VERSION ""

NS_ :

BS_:

BU_: BCM TPMS PEPS IC MP5 DDWS NV EATC TAC ESCL GW

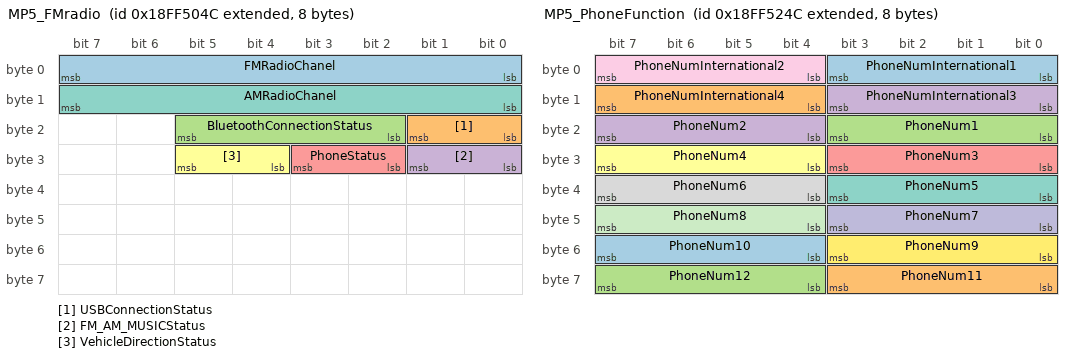
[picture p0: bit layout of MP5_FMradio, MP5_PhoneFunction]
BO_ 2566869068 MP5_FMradio: 8 MP5
 SG_ FMRadioChanel : 0|8@1+ (0.1,87.5) [87.5|108] "MHz"  IC
 SG_ USBConnectionStatus : 16|2@1+ (1,0) [0|3] ""  IC
 SG_ BluetoothConnectionStatus : 18|4@1+ (1,0) [0|15] ""  IC
 SG_ FM_AM_MUSICStatus : 24|2@1+ (1,0) [0|3] ""  IC
 SG_ PhoneStatus : 26|2@1+ (1,0) [0|3] ""  IC
 SG_ VehicleDirectionStatus : 28|2@1+ (1,0) [0|3] ""  IC
 SG_ AMRadioChanel : 8|8@1+ (9,522) [522|1629] "KHz"  IC

BO_ 2566869324 MP5_SongORName: 8 MP5
 SG_ EHC5_St_FrameType : 0|3@1+ (1,0) [0|3] ""  IC

BO_ 2566869580 MP5_PhoneFunction: 8 MP5
 SG_ PhoneNumInternational1 : 0|4@1+ (1,0) [0|9] ""  IC
 SG_ PhoneNumInternational4 : 12|4@1+ (1,0) [0|9] ""  IC
 SG_ PhoneNum1 : 16|4@1+ (1,0) [0|9] ""  IC
 SG_ PhoneNum2 : 20|4@1+ (1,0) [0|9] ""  IC
 SG_ PhoneNum3 : 24|4@1+ (1,0) [0|9] ""  IC
 SG_ PhoneNum4 : 28|4@1+ (1,0) [0|9] ""  IC
 SG_ PhoneNum5 : 32|4@1+ (1,0) [0|9] ""  IC
 SG_ PhoneNum6 : 36|4@1+ (1,0) [0|9] ""  IC
 SG_ PhoneNumInternational2 : 4|4@1+ (1,0) [0|9] ""  IC
 SG_ PhoneNum7 : 40|4@1+ (1,0) [0|9] ""  IC
 SG_ PhoneNum8 : 44|4@1+ (1,0) [0|9] ""  IC
 SG_ PhoneNum9 : 48|4@1+ (1,0) [0|9] ""  IC
 SG_ PhoneNum10 : 52|4@1+ (1,0) [0|9] ""  IC
 SG_ PhoneNum11 : 56|4@1+ (1,0) [0|9] ""  IC
 SG_ PhoneNum12 : 60|4@1+ (1,0) [0|9] ""  IC
 SG_ PhoneNumInternational3 : 8|4@1+ (1,0) [0|9] ""  IC

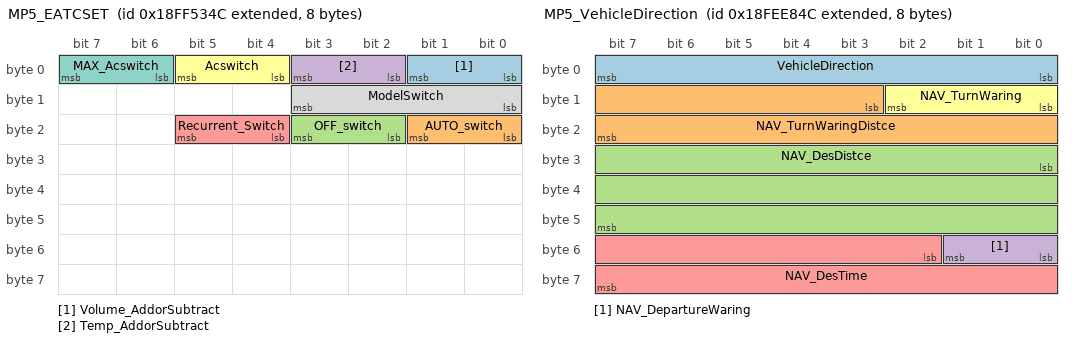
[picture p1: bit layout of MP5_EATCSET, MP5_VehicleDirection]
BO_ 2566869836 MP5_EATCSET: 8 MP5
 SG_ Volume_AddorSubtract : 0|2@1+ (1,0) [0|3] ""  EATC
 SG_ AUTO_switch : 16|2@1+ (1,0) [0|3] ""  EATC
 SG_ OFF_switch : 18|2@1+ (1,0) [0|3] ""  EATC
 SG_ Temp_AddorSubtract : 2|2@1+ (1,0) [0|3] ""  EATC
 SG_ Recurrent_Switch : 20|2@1+ (1,0) [0|3] ""  EATC
 SG_ Acswitch : 4|2@1+ (1,0) [0|3] ""  EATC
 SG_ MAX_Acswitch : 6|2@1+ (1,0) [0|3] ""  EATC
 SG_ ModelSwitch : 8|4@1+ (1,0) [0|15] ""  EATC

BO_ 2566842444 MP5_VehicleDirection: 8 MP5
 SG_ VehicleDirection : 0|8@1+ (1,0) [0|255] ""  IC
 SG_ NAV_TurnWaringDistce : 11|13@1+ (2,0) [0|10000] "m"  IC
 SG_ NAV_DesDistce : 24|24@1+ (1,0) [0|16777200] "m"  IC
 SG_ NAV_DepartureWaring : 48|2@1+ (1,0) [0|3] ""  IC
 SG_ NAV_DesTime : 50|14@1+ (1,0) [0|16383] "min分钟"  IC
 SG_ NAV_TurnWaring : 8|3@1+ (1,0) [0|7] ""  IC

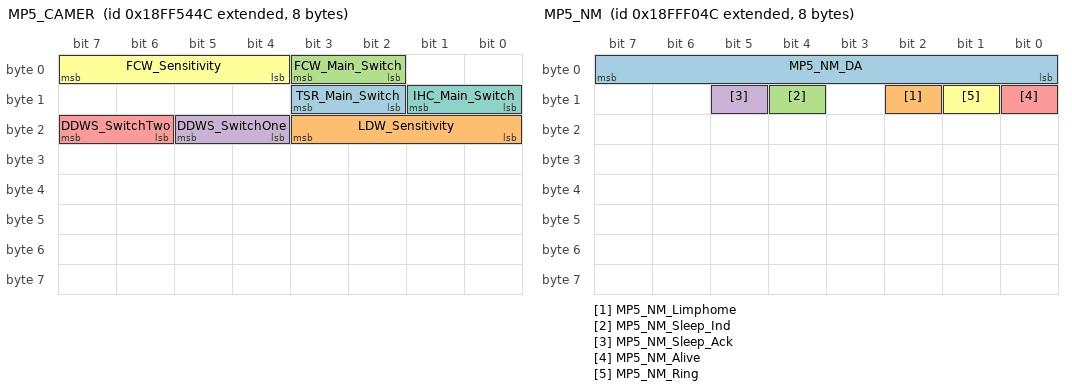
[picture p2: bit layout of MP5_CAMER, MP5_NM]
BO_ 2566870092 MP5_CAMER: 8 MP5
 SG_ TSR_Main_Switch : 10|2@1+ (1,0) [0|3] ""  GW
 SG_ LDW_Sensitivity : 16|4@1+ (1,0) [0|15] ""  GW
 SG_ FCW_Main_Switch : 2|2@1+ (1,0) [0|3] ""  GW
 SG_ DDWS_SwitchOne : 20|2@1+ (1,0) [0|3] ""  DDWS,GW
 SG_ DDWS_SwitchTwo : 22|2@1+ (1,0) [0|3] ""  DDWS,GW
 SG_ FCW_Sensitivity : 4|4@1+ (1,0) [0|15] ""  GW
 SG_ IHC_Main_Switch : 8|2@1+ (1,0) [0|3] ""  GW

BO_ 2566910028 MP5_NM: 8 MP5
 SG_ MP5_NM_DA : 0|8@1+ (1,0) [0|255] ""  BCM,PEPS,IC,EATC
 SG_ MP5_NM_Limphome : 10|1@1+ (1,0) [0|1] ""  BCM,PEPS,IC,EATC
 SG_ MP5_NM_Sleep_Ind : 12|1@1+ (1,0) [0|1] ""  BCM,PEPS,IC,EATC
 SG_ MP5_NM_Sleep_Ack : 13|1@1+ (1,0) [0|1] ""  BCM,PEPS,IC,EATC
 SG_ MP5_NM_Alive : 8|1@1+ (1,0) [0|1] ""  BCM,PEPS,IC,EATC
 SG_ MP5_NM_Ring : 9|1@1+ (1,0) [0|1] ""  BCM,PEPS,IC,EATC

BO_ 2566834764 MP5DM1CLuster: 8 MP5

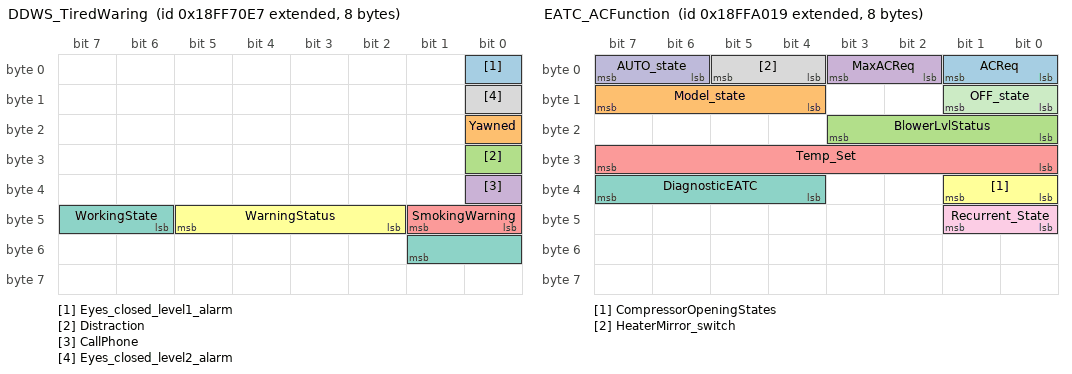
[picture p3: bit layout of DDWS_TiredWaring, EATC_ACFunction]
BO_ 2566877415 DDWS_TiredWaring: 8 DDWS
 SG_ Eyes_closed_level1_alarm : 0|1@1+ (1,0) [0|1] ""  IC,GW
 SG_ Yawned : 16|1@1+ (1,0) [0|1] ""  IC,GW
 SG_ Distraction : 24|1@1+ (1,0) [0|1] ""  IC,GW
 SG_ CallPhone : 32|1@1+ (1,0) [0|1] ""  IC,GW
 SG_ SmokingWarning : 40|2@1+ (1,0) [0|3] ""  GW
 SG_ WarningStatus : 42|4@1+ (1,0) [0|15] ""  IC,GW
 SG_ WorkingState : 46|4@1+ (1,0) [0|15] ""  IC,MP5,GW
 SG_ Eyes_closed_level2_alarm : 8|1@1+ (1,0) [0|1] ""  IC,GW

BO_ 2566877671 DDWS_CloseEyeTime: 8 DDWS
 SG_ Eyes_closed_Time : 0|8@1+ (1,0) [0|255] ""  GW

BO_ 2566834919 DDWS_DM1CLuster: 8 DDWS

BO_ 2566889497 EATC_ACFunction: 8 EATC
 SG_ ACReq : 0|2@1+ (1,0) [0|3] ""  BCM,MP5,GW
 SG_ Model_state : 12|4@1+ (1,0) [0|15] ""  MP5,GW
 SG_ BlowerLvlStatus : 16|4@1+ (1,0) [0|15] ""  MP5,GW
 SG_ MaxACReq : 2|2@1+ (1,0) [0|3] ""  MP5,GW
 SG_ Temp_Set : 24|8@1+ (1,0) [0|255] ""  MP5,GW
 SG_ CompressorOpeningStates : 32|2@1+ (1,0) [0|3] ""  BCM,GW
 SG_ DiagnosticEATC : 36|4@1+ (1,0) [0|15] ""  IC,GW
 SG_ HeaterMirror_switch : 4|2@1+ (1,0) [0|3] ""  BCM,MP5,GW
 SG_ Recurrent_State : 40|2@1+ (1,0) [0|3] ""  MP5,GW
 SG_ AUTO_state : 6|2@1+ (1,0) [0|3] ""  MP5,GW
 SG_ OFF_state : 8|2@1+ (1,0) [0|3] ""  MP5,GW

BO_ 2566841377 EATC_SHUTDN: 8 EATC
 SG_ A_C_CompressorSwitch : 22|2@1+ (1,0) [0|3] ""  GW

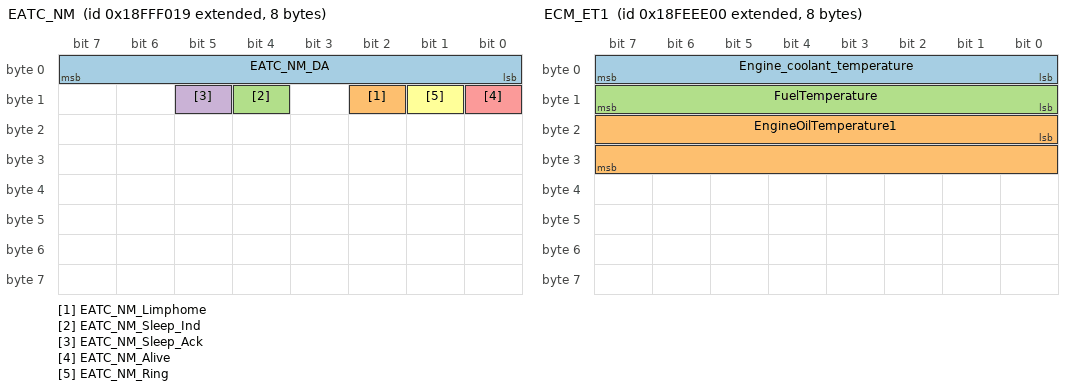
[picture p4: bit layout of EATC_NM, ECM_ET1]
BO_ 2566909977 EATC_NM: 8 EATC
 SG_ EATC_NM_DA : 0|8@1+ (1,0) [0|255] ""  BCM,PEPS,IC,MP5
 SG_ EATC_NM_Limphome : 10|1@1+ (1,0) [0|1] ""  BCM,PEPS,IC,MP5
 SG_ EATC_NM_Sleep_Ind : 12|1@1+ (1,0) [0|1] ""  BCM,PEPS,IC,MP5
 SG_ EATC_NM_Sleep_Ack : 13|1@1+ (1,0) [0|1] ""  BCM,PEPS,IC,MP5
 SG_ EATC_NM_Alive : 8|1@1+ (1,0) [0|1] ""  BCM,PEPS,IC,MP5
 SG_ EATC_NM_Ring : 9|1@1+ (1,0) [0|1] ""  BCM,PEPS,IC,MP5

BO_ 2566834713 EATCDM1CLuster: 8 EATC

BO_ 2566843904 ECM_ET1: 8 GW
 SG_ Engine_coolant_temperature : 0|8@1+ (1,-40) [-40|210] "°C"  IC,EATC
 SG_ EngineOilTemperature1 : 16|16@1+ (0.03125,-273) [-273|1735] "°C"  IC
 SG_ FuelTemperature : 8|8@1+ (1,-40) [-40|210] "°C"  IC

BO_ 2566844672 ECM_CCVS: 8 GW
 SG_ Two_speed_axle_switch : 0|2@1+ (1,0) [0|3] "" Vector__XXX
 SG_ Parking_brake_switch : 2|2@1+ (1,0) [0|3] ""  BCM,MP5,DDWS
 SG_ Cruise_Control_active : 24|2@1+ (1,0) [0|3] ""  IC,DDWS
 SG_ Cruise_Control_enable_switch : 26|2@1+ (1,0) [0|3] "" Vector__XXX
 SG_ Status_of_brake_switch : 28|2@1+ (1,0) [0|3] ""  PEPS,DDWS
 SG_ Status_of_clutch_switch : 30|2@1+ (1,0) [0|3] ""  BCM
 SG_ Cruise_Control_set_switch : 32|2@1+ (1,0) [0|3] "" Vector__XXX
 SG_ Cruise_Control_coast_switch : 34|2@1+ (1,0) [0|3] "" Vector__XXX
 SG_ Cruise_Control_resume_switch : 36|2@1+ (1,0) [0|3] "" Vector__XXX
 SG_ Cruise_Control_accelerate_switch : 38|2@1+ (1,0) [0|3] "" Vector__XXX
 SG_ Charge_Mode : 4|4@1+ (1,0) [0|15] "" Vector__XXX
 SG_ Cruise_Control_set_speed : 40|8@1+ (1,0) [0|250] "km/h" Vector__XXX
 SG_ PTO_state : 48|5@1+ (1,0) [0|31] "SED" Vector__XXX
 SG_ Cruise_Control_state : 53|3@1+ (1,0) [0|7] "SED" Vector__XXX
 SG_ IdleIncrementSwitch : 56|2@1+ (1,0) [0|3] "SED" Vector__XXX
 SG_ IdleDecrementSwitch : 58|2@1+ (1,0) [0|3] "SED" Vector__XXX
 SG_ EngineTestModeSwitch : 60|2@1+ (1,0) [0|3] "SED" Vector__XXX
 SG_ Engine_shutdown_override_switch : 62|2@1+ (1,0) [0|3] "SED" Vector__XXX
 SG_ Wheel_based_vehicle_speed : 8|16@1+ (0.00390625,0) [0|251] "km/h" Vector__XXX

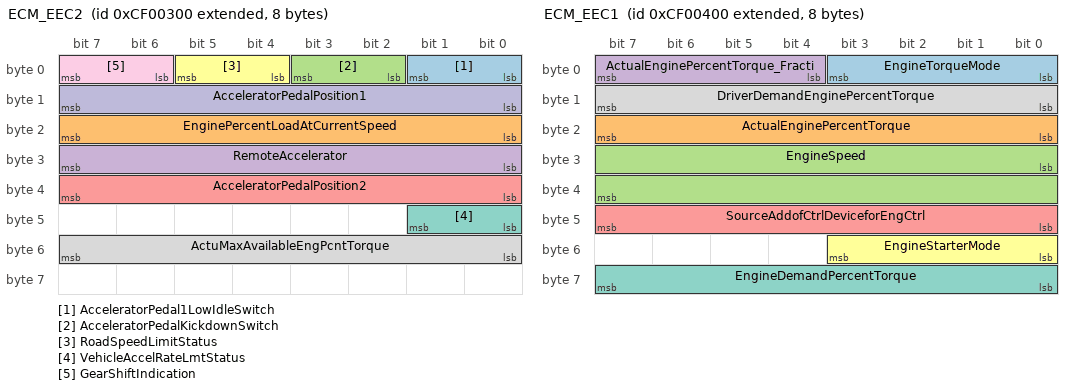
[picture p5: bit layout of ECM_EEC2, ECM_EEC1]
BO_ 2364539648 ECM_EEC2: 8 GW
 SG_ AcceleratorPedal1LowIdleSwitch : 0|2@1+ (1,0) [0|3] "" Vector__XXX
 SG_ EnginePercentLoadAtCurrentSpeed : 16|8@1+ (1,0) [0|125] "%" Vector__XXX
 SG_ AcceleratorPedalKickdownSwitch : 2|2@1+ (1,0) [0|3] "" Vector__XXX
 SG_ RemoteAccelerator : 24|8@1+ (0.4,0) [0|100] "%" Vector__XXX
 SG_ AcceleratorPedalPosition2 : 32|8@1+ (0.4,0) [0|100] "%" Vector__XXX
 SG_ RoadSpeedLimitStatus : 4|2@1+ (1,0) [0|3] "" Vector__XXX
 SG_ VehicleAccelRateLmtStatus : 40|2@1+ (1,0) [0|3] "" Vector__XXX
 SG_ ActuMaxAvailableEngPcntTorque : 48|8@1+ (0.4,0) [0|100] "%" Vector__XXX
 SG_ GearShiftIndication : 6|2@1+ (1,0) [0|3] "" Vector__XXX
 SG_ AcceleratorPedalPosition1 : 8|8@1+ (0.4,0) [0|100] "%"  DDWS

BO_ 2364539904 ECM_EEC1: 8 GW
 SG_ EngineTorqueMode : 0|4@1+ (1,0) [0|15] ""  ESCL
 SG_ ActualEnginePercentTorque : 16|8@1+ (1,-125) [0|125] "%"  ESCL
 SG_ EngineSpeed : 24|16@1+ (0.125,0) [0|8031.875] "rpm"  BCM,PEPS,IC,MP5,DDWS,EATC,ESCL
 SG_ ActualEnginePercentTorque_Fracti : 4|4@1+ (0.125,0) [0|0.875] "%" Vector__XXX
 SG_ SourceAddofCtrlDeviceforEngCtrl : 40|8@1+ (1,0) [0|253] ""  ESCL
 SG_ EngineStarterMode : 48|4@1+ (1,0) [0|15] "" Vector__XXX
 SG_ EngineDemandPercentTorque : 56|8@1- (1,-125) [0|125] ""  ESCL
 SG_ DriverDemandEnginePercentTorque : 8|8@1+ (1,-125) [0|125] "%"  ESCL

BO_ 2566841600 ECM_HOURS: 8 GW
 SG_ TotalEngineHours : 0|32@1+ (0.05,0) [0|210554060.75] ""  IC
 SG_ TotalEngineRevolutions : 32|32@1+ (1000,0) [0|4211081215000] ""  IC

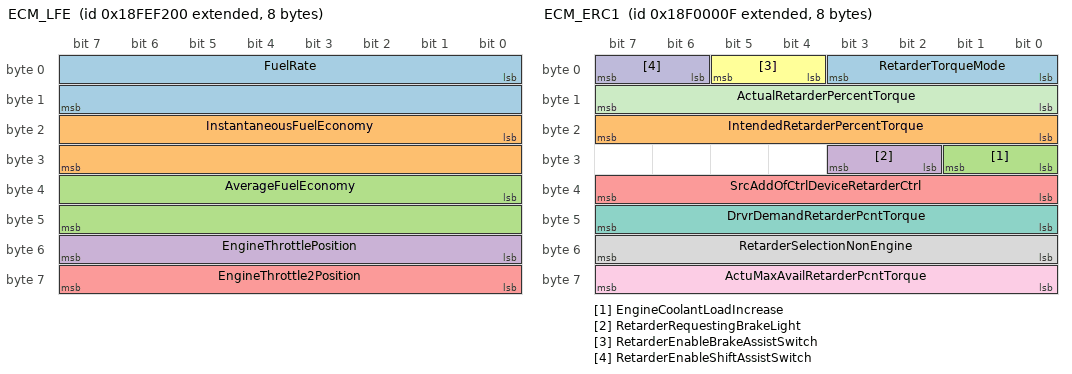
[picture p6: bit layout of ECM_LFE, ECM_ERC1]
BO_ 2566844928 ECM_LFE: 8 GW
 SG_ FuelRate : 0|16@1+ (0.05,0) [0|3212.75] "l/h"  IC
 SG_ InstantaneousFuelEconomy : 16|16@1+ (0.001953125,0) [0|125] "km/l" Vector__XXX
 SG_ AverageFuelEconomy : 32|16@1+ (0.001953125,0) [0|125] "km/l" Vector__XXX
 SG_ EngineThrottlePosition : 48|8@1+ (0.4,0) [0|100] "%" Vector__XXX
 SG_ EngineThrottle2Position : 56|8@1+ (0.4,0) [0|100] "%" Vector__XXX

BO_ 2565865487 ECM_ERC1: 8 GW
 SG_ RetarderTorqueMode : 0|4@1+ (1,0) [0|15] "" Vector__XXX
 SG_ IntendedRetarderPercentTorque : 16|8@1- (1,-125) [-125|0] "%" Vector__XXX
 SG_ EngineCoolantLoadIncrease : 24|2@1+ (1,0) [0|1] "" Vector__XXX
 SG_ RetarderRequestingBrakeLight : 26|2@1+ (1,0) [0|3] "" Vector__XXX
 SG_ SrcAddOfCtrlDeviceRetarderCtrl : 32|8@1+ (1,0) [0|255] "" Vector__XXX
 SG_ RetarderEnableBrakeAssistSwitch : 4|2@1+ (1,0) [0|3] "" Vector__XXX
 SG_ DrvrDemandRetarderPcntTorque : 40|8@1- (1,-125) [-125|0] "%" Vector__XXX
 SG_ RetarderSelectionNonEngine : 48|8@1+ (0.4,0) [0|100] "%" Vector__XXX
 SG_ ActuMaxAvailRetarderPcntTorque : 56|8@1- (1,-125) [-125|0] "%" Vector__XXX
 SG_ RetarderEnableShiftAssistSwitch : 6|2@1+ (1,0) [0|3] "" Vector__XXX
 SG_ ActualRetarderPercentTorque : 8|8@1- (1,-125) [-125|0] "%"  BCM,IC

BO_ 2566719744 ECM_HRLFC: 8 GW
 SG_ HighResolutionEngineTripFuel : 0|32@1+ (0.001,0) [0|4211081.215] "L"  IC,MP5
 SG_ HighResolutionEngTotalFuelUsed : 32|32@1+ (0.001,0) [0|4211081.215] "L"  IC,MP5

BO_ 2566842112 ECM_Vhour: 8 GW
 SG_ TotalVehicleHours : 0|32@1+ (0.05,0) [0|210554060.75] ""  IC
 SG_ TotalPowerTakeOffHours : 32|32@1+ (0.05,0) [0|210554060.75] ""  IC

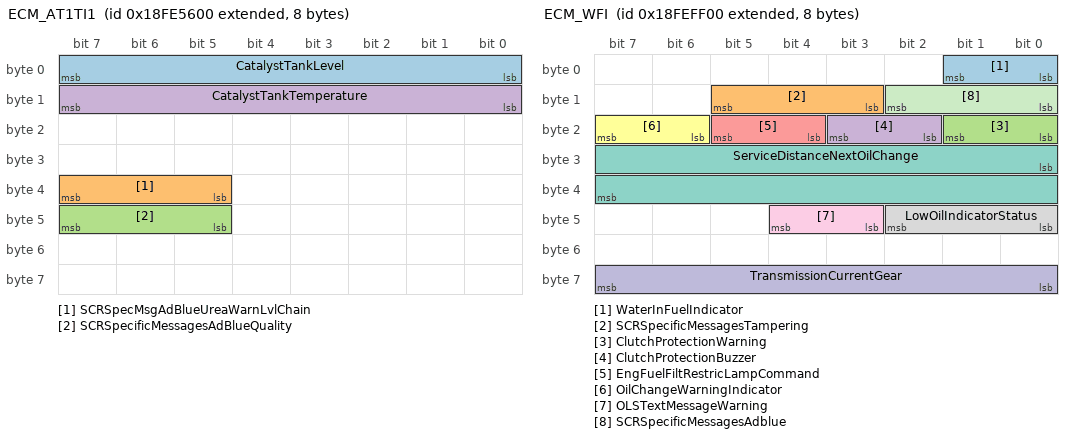
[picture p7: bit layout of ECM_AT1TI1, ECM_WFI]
BO_ 2566804992 ECM_AT1TI1: 8 GW
 SG_ CatalystTankLevel : 0|8@1+ (0.4,0) [0|100] "%"  IC
 SG_ SCRSpecMsgAdBlueUreaWarnLvlChain : 37|3@1+ (1,0) [0|7] ""  IC
 SG_ SCRSpecificMessagesAdBlueQuality : 45|3@1+ (1,0) [0|7] ""  IC
 SG_ CatalystTankTemperature : 8|8@1- (1,-40) [-40|210] "°C"  IC

BO_ 2566841344 ECM_SHUTDN: 8 GW
 SG_ IdleShutdownHasShutdownEngine : 0|2@1+ (1,0) [0|3] "" Vector__XXX
 SG_ IdleShutdownTimerFunction : 14|2@1+ (1,0) [0|3] "" Vector__XXX
 SG_ A_CHighPressureFanSwitch : 16|2@1+ (1,0) [0|3] "" Vector__XXX
 SG_ RefrigerantLowPressureSwitch : 18|2@1+ (1,0) [0|3] "" Vector__XXX
 SG_ EngIdleShutdownDriverAlertMode : 2|2@1+ (1,0) [0|3] "" Vector__XXX
 SG_ RefrigerantHighPressureSwitch : 20|2@1+ (1,0) [0|3] "" Vector__XXX
 SG_ WaitToStartLamp : 24|2@1+ (1,0) [0|3] "" Vector__XXX
 SG_ EngProtectSystemHasShutdownEng : 32|2@1+ (1,0) [0|3] "" Vector__XXX
 SG_ EngProtectSystemApproachShutdown : 34|2@1+ (1,0) [0|3] "" Vector__XXX
 SG_ EngProtectionSystemTimerOverride : 36|2@1+ (1,0) [0|3] "" Vector__XXX
 SG_ EngineProtectionSystemTimerState : 38|2@1+ (1,0) [0|3] "" Vector__XXX
 SG_ IdleShutdownTimerOverride : 4|2@1+ (1,0) [0|3] "" Vector__XXX
 SG_ EngProtectionSystemConfig : 40|2@1+ (1,0) [0|3] "" Vector__XXX
 SG_ EngineAlarmAcknowledge : 48|2@1+ (1,0) [0|3] "" Vector__XXX
 SG_ EngineAlarmOutputCommandStatus : 50|2@1+ (1,0) [0|3] "" Vector__XXX
 SG_ EngineAirShutoffCommandStatus : 52|2@1+ (1,0) [0|3] "" Vector__XXX
 SG_ EngineOverspeedTest : 54|2@1+ (1,0) [0|3] "" Vector__XXX
 SG_ EngineAirShutoffStatus : 56|2@1+ (1,0) [0|3] "" Vector__XXX
 SG_ IdleShutdownTimerState : 6|2@1+ (1,0) [0|3] "" Vector__XXX

BO_ 2566848256 ECM_WFI: 8 GW
 SG_ WaterInFuelIndicator : 0|2@1+ (1,0) [0|3] "" Vector__XXX
 SG_ SCRSpecificMessagesTampering : 11|3@1+ (1,0) [0|7] "" Vector__XXX
 SG_ ClutchProtectionWarning : 16|2@1+ (1,0) [0|3] "" Vector__XXX
 SG_ ClutchProtectionBuzzer : 18|2@1+ (1,0) [0|3] "" Vector__XXX
 SG_ EngFuelFiltRestricLampCommand : 20|2@1+ (1,0) [0|3] "" Vector__XXX
 SG_ OilChangeWarningIndicator : 22|2@1+ (1,0) [0|3] "" Vector__XXX
 SG_ ServiceDistanceNextOilChange : 24|16@1- (5,-160635) [-160635|160640] "" Vector__XXX
 SG_ LowOilIndicatorStatus : 40|3@1+ (1,0) [0|7] "" Vector__XXX
 SG_ OLSTextMessageWarning : 43|2@1+ (1,0) [0|3] "" Vector__XXX
 SG_ TransmissionCurrentGear : 56|8@1+ (1,-125) [-125|125] "" Vector__XXX
 SG_ SCRSpecificMessagesAdblue : 8|3@1+ (1,0) [0|7] "" Vector__XXX

BO_ 2566754816 ECM_EOI: 8 GW
 SG_ EngineOperatingState : 0|4@1+ (1,0) [0|3] ""  PEPS

BO_ 2566843648 ECM_CCSS: 8 GW
 SG_ ASLD_Speed : 40|8@1+ (1,0) [0|250] "km/h"  IC
 SG_ ASLD_State : 48|3@1+ (1,0) [0|7] ""  IC

BO_ 2566834688 ECM_DM1CLuster: 8 GW

BO_ 2565668608 ECM_BAME: 8 GW

BO_ 2565603072 ECM_PACKET: 8 GW

BO_ 2566852608 ECM_PassiveStart_ECU: 8 GW
 SG_ EMS_ReleaseSig_PEPS : 2|4@1+ (1,0) [0|7] ""  PEPS
 SG_ EMS_ReleaseSig_IMMO : 56|2@1+ (1,0) [0|3] ""  PEPS

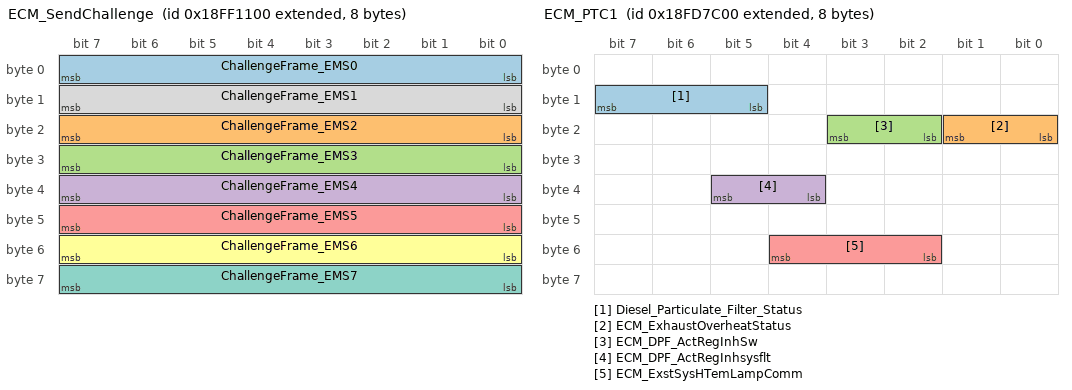
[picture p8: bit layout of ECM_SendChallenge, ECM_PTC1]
BO_ 2566852864 ECM_SendChallenge: 8 GW
 SG_ ChallengeFrame_EMS0 : 0|8@1+ (1,0) [0|255] ""  PEPS
 SG_ ChallengeFrame_EMS2 : 16|8@1+ (1,0) [0|255] ""  PEPS
 SG_ ChallengeFrame_EMS3 : 24|8@1+ (1,0) [0|255] ""  PEPS
 SG_ ChallengeFrame_EMS4 : 32|8@1+ (1,0) [0|255] ""  PEPS
 SG_ ChallengeFrame_EMS5 : 40|8@1+ (1,0) [0|255] ""  PEPS
 SG_ ChallengeFrame_EMS6 : 48|8@1+ (1,0) [0|255] ""  PEPS
 SG_ ChallengeFrame_EMS7 : 56|8@1+ (1,0) [0|255] ""  PEPS
 SG_ ChallengeFrame_EMS1 : 8|8@1+ (1,0) [0|255] ""  PEPS

BO_ 2566775040 ECM_CACI: 8 GW
 SG_ CabA_CRefrigerantCompressorOutle : 0|8@1+ (16,0) [0|4000] "kPa/bit"  EATC

BO_ 2566749184 ECM_PTC1: 8 GW
 SG_ Diesel_Particulate_Filter_Status : 13|3@1+ (1,0) [0|7] ""  IC
 SG_ ECM_ExhaustOverheatStatus : 16|2@1+ (1,0) [0|3] ""  IC
 SG_ ECM_DPF_ActRegInhSw : 18|2@1+ (1,0) [0|3] ""  IC
 SG_ ECM_DPF_ActRegInhsysflt : 36|2@1+ (1,0) [0|3] ""  IC
 SG_ ECM_ExstSysHTemLampComm : 50|3@1+ (1,0) [0|7] ""  IC

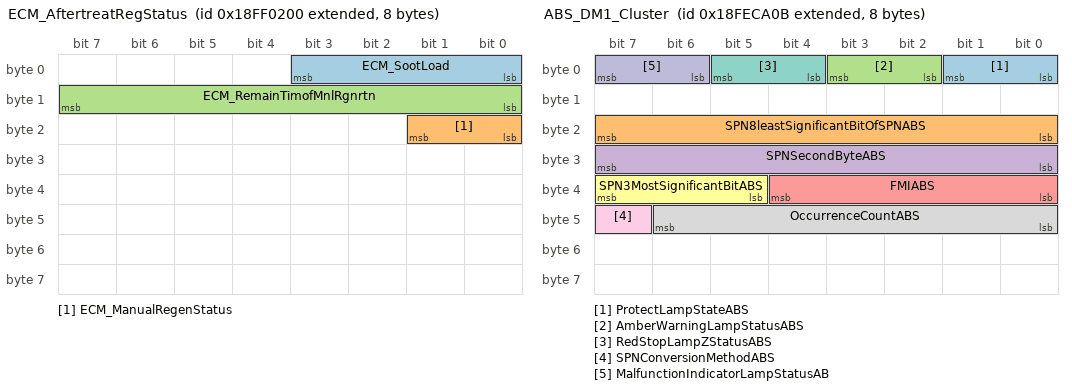
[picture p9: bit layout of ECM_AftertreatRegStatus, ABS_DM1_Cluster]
BO_ 2566849024 ECM_AftertreatRegStatus: 8 GW
 SG_ ECM_SootLoad : 0|4@1+ (1,0) [0|15] "" Vector__XXX
 SG_ ECM_ManualRegenStatus : 16|2@1+ (1,0) [0|3] ""  IC
 SG_ ECM_RemainTimofMnlRgnrtn : 8|8@1+ (1,0) [0|60] "min/bit"  IC

BO_ 2565865739 ABS_EBC1: 8 GW
 SG_ ATCEngineControlActive : 0|2@1+ (1,0) [0|3] "" Vector__XXX
 SG_ ABSoff_roadswitch : 16|2@1+ (1,0) [0|3] "" Vector__XXX
 SG_ ATCoff_roadswitch : 18|2@1+ (1,0) [0|3] "" Vector__XXX
 SG_ ATCBrakeControlActive : 2|2@1+ (1,0) [0|3] "" Vector__XXX
 SG_ ASRHillHolderSwitch : 20|2@1+ (1,0) [0|3] ""  IC
 SG_ TractionControlOverrideSwitch : 22|2@1+ (1,0) [0|3] "" Vector__XXX
 SG_ AcceleratorInterlockSwitch : 24|2@1+ (1,0) [0|3] "" Vector__XXX
 SG_ EngineDerateSwitch : 26|2@1+ (1,0) [0|3] "" Vector__XXX
 SG_ EngineAuxiliaryShutdownSwitch : 28|2@1+ (1,0) [0|3] "" Vector__XXX
 SG_ RemoteAcceleratorEnableSwitch : 30|2@1+ (1,0) [0|3] "" Vector__XXX
 SG_ EngineRetarderSelection : 32|8@1+ (0.004,0) [0|1] "" Vector__XXX
 SG_ ABSActive : 4|2@1+ (1,0) [0|3] "" Vector__XXX
 SG_ ABSfullyOperational : 40|2@1+ (1,0) [0|3] "" Vector__XXX
 SG_ EBSRedWarningSignal : 42|2@1+ (1,0) [0|3] ""  IC
 SG_ ABS_EBSamberWarningState : 44|2@1+ (1,0) [0|3] ""  IC
 SG_ ATCLampState : 46|2@1+ (1,0) [0|3] "" Vector__XXX
 SG_ SourceAddressofControllingDevice : 48|8@1+ (1,0) [0|255] "" Vector__XXX
 SG_ EBSBrakeSwitch : 6|2@1+ (1,0) [0|3] "" Vector__XXX
 SG_ BrakePedalPosition : 8|8@1+ (0.004,0) [0|1] "" Vector__XXX

BO_ 2566834699 ABS_DM1_Cluster: 8 GW
 SG_ ProtectLampStateABS : 0|2@1+ (1,0) [0|3] "" Vector__XXX
 SG_ SPN8leastSignificantBitOfSPNABS : 16|8@1+ (1,0) [0|255] "" Vector__XXX
 SG_ AmberWarningLampStatusABS : 2|2@1+ (1,0) [0|3] "" Vector__XXX
 SG_ SPNSecondByteABS : 24|8@1+ (1,0) [0|255] "" Vector__XXX
 SG_ FMIABS : 32|5@1+ (1,0) [0|31] "" Vector__XXX
 SG_ SPN3MostSignificantBitABS : 37|3@1+ (1,0) [0|7] "" Vector__XXX
 SG_ RedStopLampZStatusABS : 4|2@1+ (1,0) [0|3] "" Vector__XXX
 SG_ OccurrenceCountABS : 40|7@1+ (1,0) [0|126] "" Vector__XXX
 SG_ SPNConversionMethodABS : 47|1@1+ (1,0) [0|1] "" Vector__XXX
 SG_ MalfunctionIndicatorLampStatusAB : 6|2@1+ (1,0) [0|3] "" Vector__XXX

BO_ 2565668619 ABS_BAME: 8 GW

BO_ 2565603083 ABS_PACKET: 8 GW

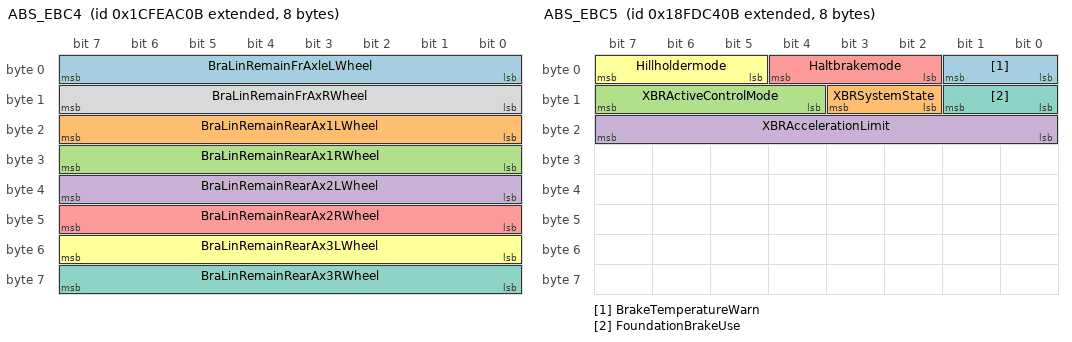
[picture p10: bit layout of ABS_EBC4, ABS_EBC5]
BO_ 2633935883 ABS_EBC4: 8 GW
 SG_ BraLinRemainFrAxleLWheel : 0|8@1+ (0.004,0) [0|1] ""  IC
 SG_ BraLinRemainRearAx1LWheel : 16|8@1+ (0.004,0) [0|1] ""  IC
 SG_ BraLinRemainRearAx1RWheel : 24|8@1+ (0.004,0) [0|1] ""  IC
 SG_ BraLinRemainRearAx2LWheel : 32|8@1+ (0.004,0) [0|1] ""  IC
 SG_ BraLinRemainRearAx2RWheel : 40|8@1+ (0.004,0) [0|1] ""  IC
 SG_ BraLinRemainRearAx3LWheel : 48|8@1+ (0.004,0) [0|1] ""  IC
 SG_ BraLinRemainRearAx3RWheel : 56|8@1+ (0.004,0) [0|1] ""  IC
 SG_ BraLinRemainFrAxRWheel : 8|8@1+ (0.004,0) [0|1] ""  IC

BO_ 2566767627 ABS_EBC5: 8 GW
 SG_ BrakeTemperatureWarn : 0|2@1+ (1,0) [0|3] "" Vector__XXX
 SG_ XBRSystemState : 10|2@1+ (1,0) [0|3] "" Vector__XXX
 SG_ XBRActiveControlMode : 12|4@1+ (1,0) [0|15] "" Vector__XXX
 SG_ XBRAccelerationLimit : 16|8@1+ (0.1,-12.5) [-12.5|12.5] "" Vector__XXX
 SG_ Haltbrakemode : 2|3@1+ (1,0) [0|7] "" Vector__XXX
 SG_ Hillholdermode : 5|3@1+ (1,0) [0|7] ""  IC
 SG_ FoundationBrakeUse : 8|2@1+ (1,0) [0|3] "" Vector__XXX

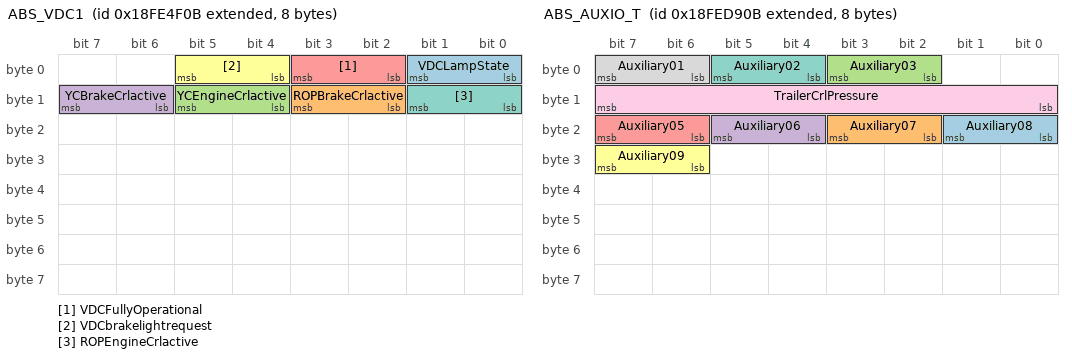
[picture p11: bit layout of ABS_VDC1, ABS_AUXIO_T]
BO_ 2566803211 ABS_VDC1: 8 GW
 SG_ VDCLampState : 0|2@1+ (1,0) [0|3] ""  IC
 SG_ ROPBrakeCrlactive : 10|2@1+ (1,0) [0|3] "" Vector__XXX
 SG_ YCEngineCrlactive : 12|2@1+ (1,0) [0|3] "" Vector__XXX
 SG_ YCBrakeCrlactive : 14|2@1+ (1,0) [0|3] "" Vector__XXX
 SG_ VDCFullyOperational : 2|2@1+ (1,0) [0|3] ""  IC
 SG_ VDCbrakelightrequest : 4|2@1+ (1,0) [0|3] ""  BCM
 SG_ ROPEngineCrlactive : 8|2@1+ (1,0) [0|3] "" Vector__XXX

BO_ 2566838539 ABS_AUXIO_T: 8 GW
 SG_ Auxiliary08 : 16|2@1+ (1,0) [0|3] "" Vector__XXX
 SG_ Auxiliary07 : 18|2@1+ (1,0) [0|3] "" Vector__XXX
 SG_ Auxiliary03 : 2|2@1+ (1,0) [0|3] "" Vector__XXX
 SG_ Auxiliary06 : 20|2@1+ (1,0) [0|3] "" Vector__XXX
 SG_ Auxiliary05 : 22|2@1+ (1,0) [0|3] "" Vector__XXX
 SG_ Auxiliary09 : 30|2@1+ (1,0) [0|3] "" Vector__XXX
 SG_ Auxiliary02 : 4|2@1+ (1,0) [0|3] ""  BCM
 SG_ Auxiliary01 : 6|2@1+ (1,0) [0|3] "" Vector__XXX
 SG_ TrailerCrlPressure : 8|8@1+ (5,0) [0|1250] "" Vector__XXX

BO_ 2365484270 IC_TCO1: 8 IC
 SG_ Tac_Output_Shaft_speed : 32|16@1+ (0.125,0) [0|8031.875] "rpm"  GW
 SG_ Tac_VehicleSpeed : 48|16@1+ (0.00390625,0) [0|250.996] "km/h"  BCM,TPMS,PEPS,MP5,DDWS,NV,EATC,TAC,ESCL,GW

BO_ 2566832622 IC_VDHR: 8 IC
 SG_ HighReTotalVehicleDistance : 0|32@1+ (5,0) [0|9999999995] "m"  BCM,PEPS,DDWS,EATC,GW
 SG_ HighResolutionTripDistanceA : 32|32@1+ (5,0) [0|9999999995] "m"  GW

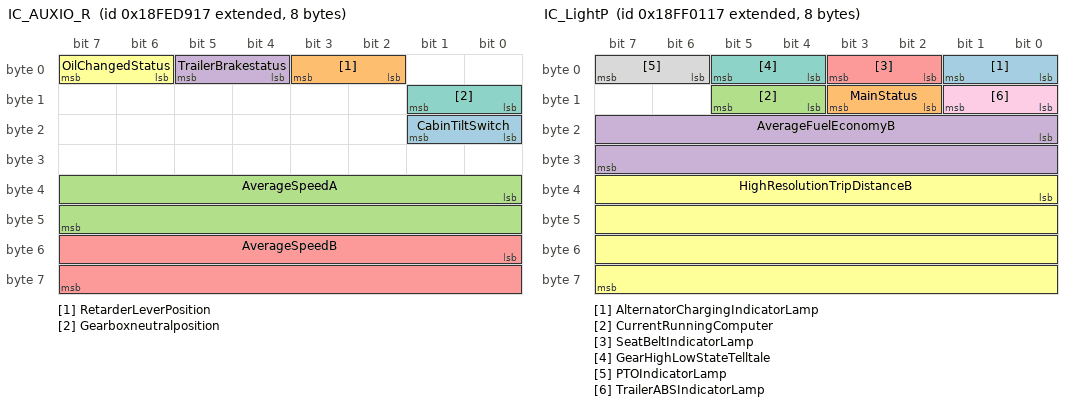
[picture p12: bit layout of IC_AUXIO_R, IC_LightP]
BO_ 2566838551 IC_AUXIO_R: 8 IC
 SG_ CabinTiltSwitch : 16|2@1+ (1,0) [0|3] ""  BCM,GW
 SG_ RetarderLeverPosition : 2|2@1+ (1,0) [0|3] ""  GW
 SG_ AverageSpeedA : 32|16@1+ (0.00390625,0) [0|250.996] "km/h"  GW
 SG_ TrailerBrakestatus : 4|2@1+ (1,0) [0|3] ""  BCM,GW
 SG_ AverageSpeedB : 48|16@1+ (0.00390625,0) [0|250.996] "km/h"  GW
 SG_ OilChangedStatus : 6|2@1+ (1,0) [0|3] ""  BCM,GW
 SG_ Gearboxneutralposition : 8|2@1+ (1,0) [0|3] ""  BCM,PEPS,GW

BO_ 2566848791 IC_LightP: 8 IC
 SG_ AlternatorChargingIndicatorLamp : 0|2@1+ (1,0) [0|3] ""  GW
 SG_ MainStatus : 10|2@1+ (1,0) [0|3] ""  MP5,GW
 SG_ CurrentRunningComputer : 12|2@1+ (1,0) [0|3] ""  GW
 SG_ AverageFuelEconomyB : 16|16@1+ (0.001953125,0) [0|125] ""  GW
 SG_ SeatBeltIndicatorLamp : 2|2@1+ (1,0) [0|3] ""  DDWS,GW
 SG_ HighResolutionTripDistanceB : 32|32@1+ (5,0) [0|21055406075] "km"  GW
 SG_ GearHighLowStateTelltale : 4|2@1+ (1,0) [0|3] ""  GW
 SG_ PTOIndicatorLamp : 6|2@1+ (1,0) [0|3] ""  GW
 SG_ TrailerABSIndicatorLamp : 8|2@1+ (1,0) [0|3] ""  GW

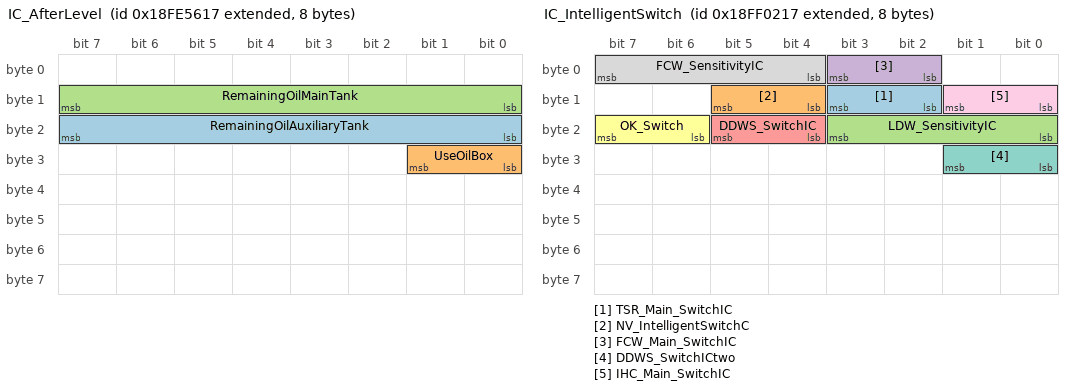
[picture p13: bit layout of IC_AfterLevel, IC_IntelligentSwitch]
BO_ 2566805015 IC_AfterLevel: 8 IC
 SG_ RemainingOilAuxiliaryTank : 16|8@1+ (0.4,0) [0|100] "%"  GW
 SG_ UseOilBox : 24|2@1+ (1,0) [0|3] ""  GW
 SG_ RemainingOilMainTank : 8|8@1+ (0.4,0) [0|100] "%"  GW

BO_ 2566849047 IC_IntelligentSwitch: 8 IC
 SG_ TSR_Main_SwitchIC : 10|2@1+ (1,0) [0|3] ""  GW
 SG_ NV_IntelligentSwitchC : 12|2@1+ (1,0) [0|3] ""  NV,GW
 SG_ LDW_SensitivityIC : 16|4@1+ (1,0) [0|15] ""  GW
 SG_ FCW_Main_SwitchIC : 2|2@1+ (1,0) [0|3] ""  GW
 SG_ DDWS_SwitchIC : 20|2@1+ (1,0) [0|3] ""  DDWS,GW
 SG_ OK_Switch : 22|2@1+ (1,0) [0|3] ""  DDWS,GW
 SG_ DDWS_SwitchICtwo : 24|2@1+ (1,0) [0|3] ""  DDWS,GW
 SG_ FCW_SensitivityIC : 4|4@1+ (1,0) [0|15] ""  GW
 SG_ IHC_Main_SwitchIC : 8|2@1+ (1,0) [0|3] ""  GW

BO_ 2565472279 IC_RequestPGN: 3 IC
 SG_ ParameterGroupNumbeingrequested : 0|24@1+ (1,0) [0|16777215] ""  GW

BO_ 2566844951 IC_LFE1_Fuel_Economy: 8 IC
 SG_ AverageFuelEconomyA : 32|16@1+ (0.001953125,0) [0|125] "km/l"  GW
 SG_ DisplayTac_VehicleSpeed : 48|16@1+ (0.00390625,0) [0|250.996] "km/h"  GW

BO_ 2561553175 IC_TirePressureSetting: 8 IC
 SG_ Tire_Location : 0|8@1+ (1,0) [0|255] "" Vector__XXX
 SG_ Reference_Tire_Setting_Conmand : 56|8@1+ (1,0) [0|255] ""  TPMS

BO_ 2566827543 IC_AIR1: 8 IC
 SG_ ServiceBrakeAirPressureCircuit1 : 16|8@1+ (8,0) [0|2000] ""  GW
 SG_ ServiceBrakeAirPressureCircuit2 : 24|8@1+ (8,0) [0|2000] ""  GW

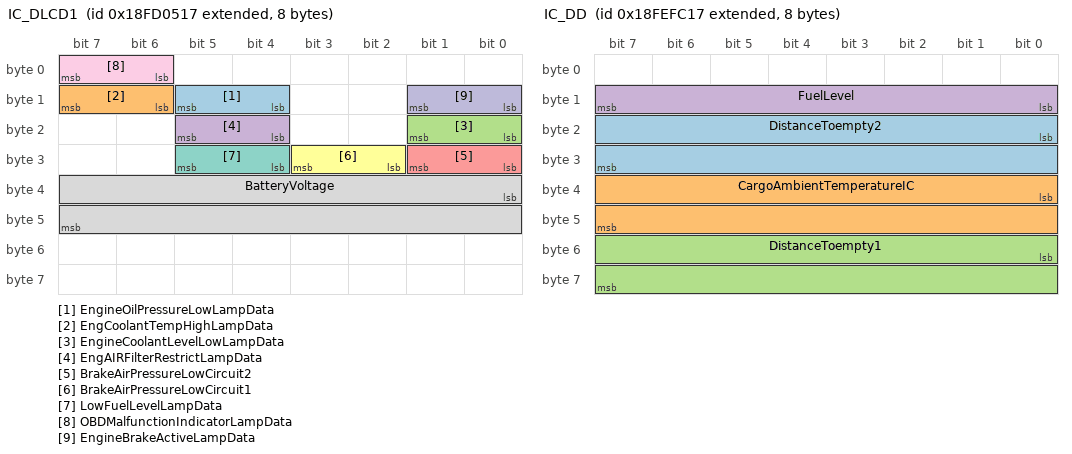
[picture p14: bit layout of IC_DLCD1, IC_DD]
BO_ 2566718743 IC_DLCD1: 8 IC
 SG_ EngineOilPressureLowLampData : 12|2@1+ (1,0) [0|3] ""  GW
 SG_ EngCoolantTempHighLampData : 14|2@1+ (1,0) [0|3] ""  GW
 SG_ EngineCoolantLevelLowLampData : 16|2@1+ (1,0) [0|3] ""  GW
 SG_ EngAIRFilterRestrictLampData : 20|2@1+ (1,0) [0|3] ""  GW
 SG_ BrakeAirPressureLowCircuit2 : 24|2@1+ (1,0) [0|3] ""  GW
 SG_ BrakeAirPressureLowCircuit1 : 26|2@1+ (1,0) [0|3] ""  GW
 SG_ LowFuelLevelLampData : 28|2@1+ (1,0) [0|3] ""  GW
 SG_ BatteryVoltage : 32|16@1+ (0.557,0.1) [0.1|35] "V"  GW
 SG_ OBDMalfunctionIndicatorLampData : 6|2@1+ (1,0) [0|3] ""  GW
 SG_ EngineBrakeActiveLampData : 8|2@1+ (1,0) [0|3] ""  GW

BO_ 2566847511 IC_DD: 8 IC
 SG_ DistanceToempty2 : 16|16@1+ (1,0) [0|65535] ""  GW
 SG_ CargoAmbientTemperatureIC : 32|16@1+ (0.03125,-273) [-40|120] ""  EATC,GW
 SG_ DistanceToempty1 : 48|16@1+ (1,0) [0|65535] ""  GW
 SG_ FuelLevel : 8|8@1+ (0.4,0) [0|100] "%"  GW

BO_ 2566843415 IC_VIN: 18 IC
 SG_ VehicleIdentificationNumber1 : 0|64@1+ (1,0) [0|0] ""  GW
 SG_ VehicleIdentificationNumber3 : 136|8@1+ (1,0) [0|0] ""  GW
 SG_ DelimiterIC : 144|8@1+ (1,0) [0|255] ""  GW
 SG_ VehicleIdentificationNumber2 : 72|64@1+ (1,0) [0|0] ""  GW

BO_ 2565668631 IC_vin_BAME: 8 IC

BO_ 2565603095 IC_vin_PACKET: 8 IC

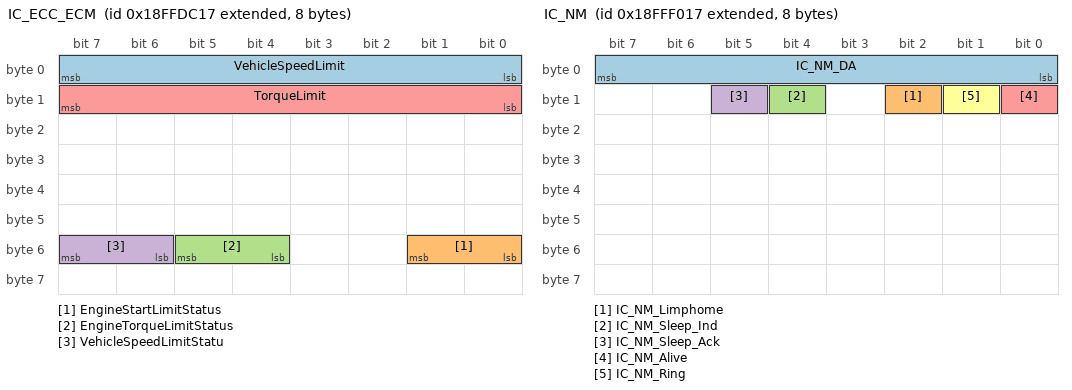
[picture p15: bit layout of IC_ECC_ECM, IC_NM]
BO_ 2566904855 IC_ECC_ECM: 8 IC
 SG_ VehicleSpeedLimit : 0|8@1+ (1,0) [0|255] "km/h"  GW
 SG_ EngineStartLimitStatus : 48|2@1+ (1,0) [0|3] ""  GW
 SG_ EngineTorqueLimitStatus : 52|2@1+ (1,0) [0|3] ""  GW
 SG_ VehicleSpeedLimitStatu : 54|2@1+ (1,0) [0|3] ""  GW
 SG_ TorqueLimit : 8|8@1+ (1,-125) [0|125] "%"  GW

BO_ 2566909975 IC_NM: 8 IC
 SG_ IC_NM_DA : 0|8@1+ (1,0) [0|255] ""  BCM,PEPS,MP5,EATC
 SG_ IC_NM_Limphome : 10|1@1+ (1,0) [0|1] ""  BCM,PEPS,MP5,EATC
 SG_ IC_NM_Sleep_Ind : 12|1@1+ (1,0) [0|1] ""  BCM,PEPS,MP5,EATC
 SG_ IC_NM_Sleep_Ack : 13|1@1+ (1,0) [0|1] ""  BCM,PEPS,MP5,EATC
 SG_ IC_NM_Alive : 8|1@1+ (1,0) [0|1] ""  BCM,PEPS,MP5,EATC
 SG_ IC_NM_Ring : 9|1@1+ (1,0) [0|1] ""  BCM,PEPS,MP5,EATC

BO_ 2566834711 ICDM1CLuster: 8 IC

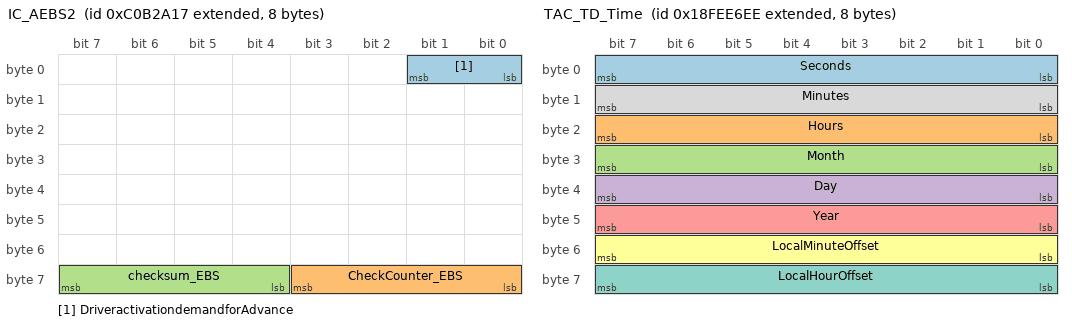
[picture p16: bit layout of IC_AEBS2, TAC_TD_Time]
BO_ 2349541911 IC_AEBS2: 8 IC
 SG_ DriveractivationdemandforAdvance : 0|2@1+ (1,0) [0|3] ""  GW
 SG_ CheckCounter_EBS : 56|4@1+ (1,0) [0|15] ""  GW
 SG_ checksum_EBS : 60|4@1+ (1,0) [0|15] ""  GW

BO_ 2566842094 TAC_TD_Time: 8 TAC
 SG_ Seconds : 0|8@1+ (0.25,0) [0|59.75] "s"  BCM,IC,MP5,DDWS,NV,EATC,GW
 SG_ Hours : 16|8@1+ (1,0) [0|23] "hr"  BCM,IC,MP5,DDWS,NV,EATC,GW
 SG_ Month : 24|8@1+ (1,0) [0|12] "month"  BCM,IC,MP5,DDWS,NV,EATC,GW
 SG_ Day : 32|8@1+ (0.25,0) [1|31] "days"  BCM,IC,MP5,DDWS,NV,EATC,GW
 SG_ Year : 40|8@1+ (1,1985) [1985|2235] "year"  BCM,IC,MP5,DDWS,NV,EATC,GW
 SG_ LocalMinuteOffset : 48|8@1+ (1,-125) [-59|59] "min"  BCM,IC,MP5,DDWS,NV,EATC,GW
 SG_ LocalHourOffset : 56|8@1+ (1,-125) [-23|23] "hour"  BCM,IC,MP5,DDWS,NV,EATC,GW
 SG_ Minutes : 8|8@1+ (1,0) [0|59] "min"  BCM,IC,MP5,DDWS,NV,EATC,GW

BO_ 2365526254 TAC_DCNumber: 19 TAC
 SG_ DriverCardNumber : 0|144@1+ (1,0) [0|0] ""  GW
 SG_ DriverCardState : 150|2@1+ (1,0) [0|3] ""  GW

BO_ 2364342254 TAC_DCNumberBAME: 8 TAC

BO_ 2364276718 TAC_DCNumberPACKET: 8 TAC

BO_ 2633943790 TACDM1CLuster: 8 TAC

CM_ "Version:0.5,Date:2018/10/17,Author:Wang Zijia,Check:,Review:,Approval:,Description:()
1、更新IC,MP5的智能调节软开关功能的定义未操作的定义。MP5_CAMER，0x18FF544C；IC_IntelligentSwitch，0x18FF0217；
2、BCM增加DPF开关BCM_CM1，网关需要转到动力CAN；
3、更正PEPS信号：ESCL - 2_PS，18DD4D34，的第一，二个信号的起始位更正；
4、TBOX增加接收BCM_OELight，0x0CFDCC21，HazardLightSwitchSignal；IC_AUXIO_R，0x18FED917，GearboxNeutralPosition；ECM_IC1_Inlet：0x18FEF600， EngineBoostPressure 信号
5、GW不在将TBOX_DM1CLuster报文转发到BCAN
6、增加TAC_TD_Time报文，TBOX发，IC收，增加IC_VIN报文TBOX收;
Version:0.4,Date:2018/10/8,Author:Wang Zijia,Check:,Review:,Approval:,Description:()1、新增BCM_CCVS报文中增加PTO MODE信号；0x18FEF121，ECM收
2、TCU新增接收EBC5信号；
3、TCU_TCDIS 0x18FF8503信号仪表需要接受，TCM_ETC7信号增加仪表接收
4、ABS需要接收气压信号，网关和VCU需要把IC_AIR1，0x18FEAE17转到动力CAN上；ABS增加接收Parking_brake_switch/Status_of_clutch_switch/IC_TCO1/IC_VDHR
5、网关和VCU需要将Cam_AEBS1，0x0CF02F2A从动力CAN转到";
CM_ SG_ 2566869068 FMRadioChanel "FM收音机频率";
CM_ SG_ 2566869068 USBConnectionStatus "USB连接状态";
CM_ SG_ 2566869068 BluetoothConnectionStatus "蓝牙连接状态";
CM_ SG_ 2566869068 FM_AM_MUSICStatus "FM/AM/MUSIC状态标志位";
CM_ SG_ 2566869068 PhoneStatus "电话状态";
CM_ SG_ 2566869068 VehicleDirectionStatus "导航状态";
CM_ SG_ 2566869068 AMRadioChanel "AM收音机频率";
CM_ BO_ 2566869324 "当数据场长度大于8个字节时按照J1939 TP层多包传输协议定义进行发送 MP5_Song_BAM 0x18ECFF4C   MP5_Song_PACKET  0x18EBFF4C";
CM_ SG_ 2566869324 EHC5_St_FrameType "中英文歌名";
CM_ SG_ 2566869580 PhoneNumInternational1 "国际代码1";
CM_ SG_ 2566869580 PhoneNumInternational4 "国际代码4";
CM_ SG_ 2566869580 PhoneNum1 "手机号码第1位/固定电话第1位";
CM_ SG_ 2566869580 PhoneNum2 "手机号码第2位/固定电话第2位";
CM_ SG_ 2566869580 PhoneNum3 "手机号码第3位/固定电话第3位";
CM_ SG_ 2566869580 PhoneNum4 "手机号码第4位/固定电话第4位";
CM_ SG_ 2566869580 PhoneNum5 "手机号码第5位/固定电话第5位";
CM_ SG_ 2566869580 PhoneNum6 "手机号码第6位/固定电话第6位";
CM_ SG_ 2566869580 PhoneNumInternational2 "国际代码2";
CM_ SG_ 2566869580 PhoneNum7 "手机号码第7位/固定电话第7位";
CM_ SG_ 2566869580 PhoneNum8 "手机号码第8位/固定电话第8位";
CM_ SG_ 2566869580 PhoneNum9 "手机号码第9位/固定电话第9位";
CM_ SG_ 2566869580 PhoneNum10 "手机号码第10位/固定电话第10位";
CM_ SG_ 2566869580 PhoneNum11 "手机号码第11位/固定电话第11位";
CM_ SG_ 2566869580 PhoneNum12 "手机号码第12位/固定电话第12位";
CM_ SG_ 2566869580 PhoneNumInternational3 "国际代码3";
CM_ SG_ 2566869836 Volume_AddorSubtract "风量加减";
CM_ SG_ 2566869836 AUTO_switch "AUTO按键";
CM_ SG_ 2566869836 OFF_switch "OFF按键";
CM_ SG_ 2566869836 Temp_AddorSubtract "温度加减";
CM_ SG_ 2566869836 Recurrent_Switch "内循环功能按键";
CM_ SG_ 2566869836 Acswitch "AC开关";
CM_ SG_ 2566869836 MAX_Acswitch "MAX AC开关";
CM_ SG_ 2566869836 ModelSwitch "模式开关";
CM_ SG_ 2566842444 VehicleDirection "车辆行驶方向(东、东南、南、西南、西、西北、北、东北)";
CM_ SG_ 2566842444 NAV_TurnWaringDistce "离转向点距离";
CM_ SG_ 2566842444 NAV_DesDistce "导航目的地距离信号";
CM_ SG_ 2566842444 NAV_DepartureWaring "偏离当前道路信号";
CM_ SG_ 2566842444 NAV_DesTime "距离目的地时间";
CM_ SG_ 2566842444 NAV_TurnWaring "地图路径转向信号";
CM_ SG_ 2566870092 TSR_Main_Switch "交通限速标指提醒开关";
CM_ SG_ 2566870092 LDW_Sensitivity "LDW敏感级别";
CM_ SG_ 2566870092 FCW_Main_Switch "前车碰撞报警开关";
CM_ SG_ 2566870092 DDWS_SwitchOne "DDWS一级开关";
CM_ SG_ 2566870092 DDWS_SwitchTwo "DDWS二三级开关";
CM_ SG_ 2566870092 FCW_Sensitivity "前车碰撞报警敏感级别";
CM_ SG_ 2566870092 IHC_Main_Switch "自动大灯开关";
CM_ SG_ 2566910028 MP5_NM_DA "MP5网络管理报文目的地址";
CM_ SG_ 2566910028 MP5_NM_Limphome "Limphome类型网络管理报文";
CM_ SG_ 2566910028 MP5_NM_Sleep_Ind "MP5睡眠指示";
CM_ SG_ 2566910028 MP5_NM_Sleep_Ack "MP5睡眠应答";
CM_ SG_ 2566910028 MP5_NM_Alive "Alive类型网络管理报文";
CM_ SG_ 2566910028 MP5_NM_Ring "Ring类型网络管理报文";
CM_ BO_ 2566834764 "默认发送数据见诊断规范定义,当数据场长度大于8个字节时按照J1939 TP层多包传输协议定义进行发送  DM1CLuster_BAM 0x1CECFF4C   DM1CLuster_PACKET 0x1CEBFF4C";
CM_ SG_ 2566877415 Eyes_closed_level1_alarm "一级闭眼检测";
CM_ SG_ 2566877415 Yawned "打哈欠检测";
CM_ SG_ 2566877415 Distraction "注意力分散检测";
CM_ SG_ 2566877415 CallPhone "打手机检测";
CM_ SG_ 2566877415 SmokingWarning "吸烟检测";
CM_ SG_ 2566877415 WarningStatus "报警状态";
CM_ SG_ 2566877415 WorkingState "工作状态";
CM_ SG_ 2566877415 Eyes_closed_level2_alarm "二级闭眼检测";
CM_ SG_ 2566877671 Eyes_closed_Time "闭眼时长";
CM_ BO_ 2566834919 "默认发送数据见诊断规范定义,当数据场长度大于8个字节时按照J1939 TP层多包传输协议定义进行发送 DM1CLuster_BAM 0x1CECFFE7   DM1CLuster_PACKET 0x1CEBFFE7";
CM_ SG_ 2566889497 ACReq "AC请求信号";
CM_ SG_ 2566889497 Model_state "模式状态";
CM_ SG_ 2566889497 BlowerLvlStatus "鼓风机风量档位";
CM_ SG_ 2566889497 MaxACReq "最大AC请求信号";
CM_ SG_ 2566889497 Temp_Set "温度设置(17.5显示Low，18..........31.5显示high
00表示17.5，01表示18，02表示18.5，03表示19.....1C表示31.5)";
CM_ SG_ 2566889497 CompressorOpeningStates "压缩机开启信号";
CM_ SG_ 2566889497 DiagnosticEATC "EATC故障信号";
CM_ SG_ 2566889497 HeaterMirror_switch "后视镜加热开关";
CM_ SG_ 2566889497 Recurrent_State "循环状态";
CM_ SG_ 2566889497 AUTO_state "AUTO状态";
CM_ SG_ 2566889497 OFF_state "OFF状态";
CM_ SG_ 2566841377 A_C_CompressorSwitch "A_C压力开关";
CM_ SG_ 2566909977 EATC_NM_DA "EATC网络管理报文目的地址";
CM_ SG_ 2566909977 EATC_NM_Limphome "Limphome类型网络管理报文";
CM_ SG_ 2566909977 EATC_NM_Sleep_Ind "EATC睡眠指示";
CM_ SG_ 2566909977 EATC_NM_Sleep_Ack "EATC睡眠应答";
CM_ SG_ 2566909977 EATC_NM_Alive "Alive类型网络管理报文";
CM_ SG_ 2566909977 EATC_NM_Ring "Ring类型网络管理报文";
CM_ BO_ 2566834713 "默认发送数据见诊断规范定义,当数据场长度大于8个字节时按照J1939 TP层多包传输协议定义进行发送 DM1CLuster_BAM 0x1CECFF19  DM1CLuster_PACKET 0x1CEBFF19";
CM_ SG_ 2566843904 Engine_coolant_temperature "发动机冷却液温度(发动机水温)";
CM_ SG_ 2566843904 EngineOilTemperature1 "机油温度";
CM_ SG_ 2566843904 FuelTemperature "燃油温度";
CM_ SG_ 2566844672 Parking_brake_switch "手刹";
CM_ SG_ 2566844672 Cruise_Control_active "巡航控制激活";
CM_ SG_ 2566844672 Cruise_Control_enable_switch "巡航使能开关";
CM_ SG_ 2566844672 Status_of_brake_switch "刹车开关";
CM_ SG_ 2566844672 Status_of_clutch_switch "离合开关状态";
CM_ SG_ 2566844672 Cruise_Control_set_speed "巡航设定车速";
CM_ SG_ 2566844672 PTO_state "PTO状态";
CM_ SG_ 2566844672 Cruise_Control_state "巡航控制状态";
CM_ SG_ 2364539648 AcceleratorPedal1LowIdleSwitch "加速踏板低怠速开关 ";
CM_ SG_ 2364539648 EnginePercentLoadAtCurrentSpeed "发动机转速百分比负荷 ";
CM_ SG_ 2364539648 AcceleratorPedalKickdownSwitch "踏板开关 ";
CM_ SG_ 2364539648 RemoteAccelerator "远程油门";
CM_ SG_ 2364539648 AcceleratorPedalPosition2 "踏板位置 2";
CM_ SG_ 2364539648 RoadSpeedLimitStatus "速度限制状态（常设为未激活状态）";
CM_ SG_ 2364539648 VehicleAccelRateLmtStatus "车辆加速率极限状态";
CM_ SG_ 2364539648 ActuMaxAvailableEngPcntTorque "实际最大可用发动机-百分之扭矩";
CM_ SG_ 2364539648 GearShiftIndication "换档提示";
CM_ SG_ 2364539648 AcceleratorPedalPosition1 "踏板位置 1";
CM_ SG_ 2364539904 EngineTorqueMode "发动机扭矩模式";
CM_ SG_ 2364539904 ActualEnginePercentTorque "发动机实际扭矩百分比";
CM_ SG_ 2364539904 EngineSpeed "发动机转速";
CM_ SG_ 2364539904 ActualEnginePercentTorque_Fracti "发动机实际扭矩百分比精度（需ECM确认能否发送）
This parameter displays an additional torque in percent of the reference engine torque. 
When the MSB is set to 1, this parameter is not available.  When the MSB is set to 0, bits 1 to 3 indicate the desired torque with resolution of 0.125%/bit . Range is from 0 to 0.875% of reference torque.  
The parameter is used in combination with SPN 513 Actual Engine Torque. The resulting actual engine torque will be calculated by adding these two parameters. 
Additional torque representations
For example, if SPN 513 = 150 (or 25%) and this parameter is 0100, the torque would be 25.5%.
If SPN 513 = 175 (or 50%) and this parameter is 0001, the torque would be 50.125%
If SPN 513 = 175 (or 50%) and this parameter is 1111, the torque would remain 50% (no high resolution available)";
CM_ SG_ 2364539904 SourceAddofCtrlDeviceforEngCtrl "控制发动机设备源地址 ";
CM_ SG_ 2364539904 EngineStarterMode "发动机起动方式 ";
CM_ SG_ 2364539904 EngineDemandPercentTorque "发动机需求扭矩百分比";
CM_ SG_ 2364539904 DriverDemandEnginePercentTorque "驾驶员指令百分比扭矩";
CM_ SG_ 2566844928 FuelRate "燃油消耗率";
CM_ SG_ 2566844928 InstantaneousFuelEconomy "瞬时油耗";
CM_ SG_ 2566844928 AverageFuelEconomy "平均油耗";
CM_ SG_ 2566844928 EngineThrottlePosition "发动机节气门位置 ";
CM_ SG_ 2566804992 CatalystTankLevel "尿素液位";
CM_ SG_ 2566804992 SCRSpecMsgAdBlueUreaWarnLvlChain "尿素状态（需不需要加尿素）";
CM_ SG_ 2566841344 IdleShutdownHasShutdownEngine "怠速关闭已关闭发动机";
CM_ SG_ 2566841344 IdleShutdownTimerFunction "怠速关闭定时器功能  ";
CM_ SG_ 2566841344 A_CHighPressureFanSwitch "高压风扇开关";
CM_ SG_ 2566841344 EngIdleShutdownDriverAlertMode "怠速关闭驱动器警报模式";
CM_ SG_ 2566841344 WaitToStartLamp "等待启动指示灯 ";
CM_ SG_ 2566841344 EngProtectSystemHasShutdownEng "发动机保护系统已关闭发动机";
CM_ SG_ 2566841344 EngProtectSystemApproachShutdown "发动机保护系统接近关闭";
CM_ SG_ 2566841344 EngineProtectionSystemTimerState "发动机保护系统定时器状态";
CM_ SG_ 2566841344 IdleShutdownTimerOverride "怠速关闭定时器溢出 ";
CM_ SG_ 2566841344 EngProtectionSystemConfig "发动机保护系统配置";
CM_ SG_ 2566841344 IdleShutdownTimerState "怠速关闭定时器状态";
CM_ SG_ 2566848256 SCRSpecificMessagesTampering "SCR Specific Messages - Tampering Faults & Blocked EGR";
CM_ SG_ 2566848256 ClutchProtectionWarning "Clutch Protection Warning";
CM_ SG_ 2566848256 ClutchProtectionBuzzer "Clutch Protection Buzzer";
CM_ SG_ 2566848256 EngFuelFiltRestricLampCommand "Engine Fuel Filter Restriction Lamp Command";
CM_ SG_ 2566848256 OilChangeWarningIndicator "Oil Change Warning Indicator";
CM_ SG_ 2566848256 ServiceDistanceNextOilChange "Service Distance to Next Oil Change";
CM_ SG_ 2566848256 LowOilIndicatorStatus "Low Oil indicator status";
CM_ SG_ 2566848256 OLSTextMessageWarning "OLS Text Message Warning";
CM_ SG_ 2566848256 TransmissionCurrentGear "Transmission Current Gear";
CM_ SG_ 2566848256 SCRSpecificMessagesAdblue "SCR Specific Messages - Adblue Consumption& Dosing Interruption Chain";
CM_ SG_ 2566754816 EngineOperatingState "发动机运行状态
(需要ECM确认能否发送)";
CM_ SG_ 2566843648 ASLD_Speed "ASLD速度";
CM_ SG_ 2566843648 ASLD_State "ASLD状态";
CM_ BO_ 2566834688 "默认发送数据见诊断规范定义,当数据场长度大于8个字节时按照J1939 TP层多包传输协议定义进行发送 DM1CLuster_BAM 0x1CECFF00  DM1CLuster_PACKET 0x1CEBFF00";
CM_ BO_ 2565668608 "ECM_DM1CLuster多包传输的时候发";
CM_ BO_ 2565603072 "ECM_DM1CLuster多包传输的时候发";
CM_ SG_ 2566852608 EMS_ReleaseSig_PEPS "Indicate the start or start cancel command response";
CM_ SG_ 2566852608 EMS_ReleaseSig_IMMO "防盗认证结果";
CM_ SG_ 2566852864 ChallengeFrame_EMS0 "发动机防盗随机数请求";
CM_ SG_ 2566852864 ChallengeFrame_EMS2 "发动机防盗随机数请求";
CM_ SG_ 2566852864 ChallengeFrame_EMS3 "发动机防盗随机数请求";
CM_ SG_ 2566852864 ChallengeFrame_EMS4 "发动机防盗随机数请求";
CM_ SG_ 2566852864 ChallengeFrame_EMS5 "发动机防盗随机数请求";
CM_ SG_ 2566852864 ChallengeFrame_EMS6 "发动机防盗随机数请求";
CM_ SG_ 2566852864 ChallengeFrame_EMS7 "发动机防盗随机数请求";
CM_ SG_ 2566852864 ChallengeFrame_EMS1 "发动机防盗随机数请求";
CM_ SG_ 2566775040 CabA_CRefrigerantCompressorOutle "空调系统高压压力＞2.7MPa后，压缩机停止工作；当压力降到＜2.0MPa后，压缩机开启；空调系统高压压力＞0.21MPa后，压缩机开启；当压力降到＜0.2MPa后，压缩机停止工作；";
CM_ BO_ 2566749184 "国六发动机";
CM_ SG_ 2566749184 Diesel_Particulate_Filter_Status "再生请求";
CM_ SG_ 2566749184 ECM_ExhaustOverheatStatus "排气过热状态";
CM_ SG_ 2566749184 ECM_DPF_ActRegInhSw "开关抑制微粒过滤器主动再生";
CM_ SG_ 2566749184 ECM_DPF_ActRegInhsysflt "系统错误抑制颗粒过滤器主动再生";
CM_ SG_ 2566749184 ECM_ExstSysHTemLampComm "排气温度过高";
CM_ BO_ 2566849024 "国六发动机";
CM_ SG_ 2566849024 ECM_ManualRegenStatus "手动再生状态";
CM_ SG_ 2566849024 ECM_RemainTimofMnlRgnrtn "DPF再生剩余时间";
CM_ SG_ 2565865739 ATCEngineControlActive "ATC发动机控制激活";
CM_ SG_ 2565865739 ABSoff_roadswitch "ABS  越野开关";
CM_ SG_ 2565865739 ATCoff_roadswitch "ATC越野开关";
CM_ SG_ 2565865739 ATCBrakeControlActive "ATC制动控制激活 ";
CM_ SG_ 2565865739 ASRHillHolderSwitch "HSA开关";
CM_ SG_ 2565865739 TractionControlOverrideSwitch "牵引力控制开关（ASR不发）";
CM_ SG_ 2565865739 AcceleratorInterlockSwitch "加速禁止开关，目前没用，发11";
CM_ SG_ 2565865739 EngineDerateSwitch "转矩限制开关目前没用，发11";
CM_ SG_ 2565865739 EngineAuxiliaryShutdownSwitch "发送机熄火开关，目前没用，发11";
CM_ SG_ 2565865739 RemoteAcceleratorEnableSwitch "远程加速器使能开关，目前没用，发11";
CM_ SG_ 2565865739 EngineRetarderSelection "目前没用，发11";
CM_ SG_ 2565865739 ABSActive "防抱系统（ABS）激活";
CM_ SG_ 2565865739 ABSfullyOperational "ABS  全工作状态";
CM_ SG_ 2565865739 EBSRedWarningSignal "EBS红色报警状态";
CM_ SG_ 2565865739 ABS_EBSamberWarningState "ABS/EBS黄色警告状态（动力车辆）";
CM_ SG_ 2565865739 ATCLampState "ATC 信息信号(ASR)";
CM_ SG_ 2565865739 SourceAddressofControllingDevice "不发";
CM_ SG_ 2565865739 EBSBrakeSwitch "制动踏板踩下";
CM_ SG_ 2565865739 BrakePedalPosition "制动踏板位置（需要确认下ECM发了，EBS能否发送）";
CM_ BO_ 2566834699 "默认发送数据见诊断规范定义,当数据场长度大于8个字节时按照J1939 TP层多包传输协议定义进行发送 DM1CLuster_BAM 0x1CECFF0B   DM1CLuster_PACKET 0x1CEBFF0B";
CM_ SG_ 2566834699 ProtectLampStateABS "（SVS lamp） status/SVS灯状态";
CM_ SG_ 2566834699 SPN8leastSignificantBitOfSPNABS "SPN 第一字节";
CM_ SG_ 2566834699 AmberWarningLampStatusABS "环境警告灯状态";
CM_ SG_ 2566834699 SPNSecondByteABS "SPN 第二字节";
CM_ SG_ 2566834699 FMIABS "FMI ";
CM_ SG_ 2566834699 SPN3MostSignificantBitABS "SPN MSB";
CM_ SG_ 2566834699 RedStopLampZStatusABS "红色停止灯状态 ";
CM_ SG_ 2566834699 OccurrenceCountABS "当前故障计数";
CM_ SG_ 2566834699 SPNConversionMethodABS "SPN 转换模式";
CM_ SG_ 2566834699 MalfunctionIndicatorLampStatusAB "MIL 灯状态";
CM_ BO_ 2565668619 "ABS_DM1_Cluster多包传输的时候发";
CM_ BO_ 2565603083 "ABS_DM1_Cluster多包传输的时候发";
CM_ SG_ 2633935883 BraLinRemainFrAxleLWheel "前轴制动衬片剩余前轴，左前轮";
CM_ SG_ 2633935883 BraLinRemainRearAx1LWheel "前轴制动衬片剩余后轴1，左后轮";
CM_ SG_ 2633935883 BraLinRemainRearAx1RWheel "前轴制动衬片剩余后轴1，右后轮";
CM_ SG_ 2633935883 BraLinRemainRearAx2LWheel "前轴制动衬片剩余后轴2，左后轮";
CM_ SG_ 2633935883 BraLinRemainRearAx2RWheel "前轴制动衬片剩余后轴2，右后轮";
CM_ SG_ 2633935883 BraLinRemainRearAx3LWheel "前轴制动衬片剩余后轴3，左后轮";
CM_ SG_ 2633935883 BraLinRemainRearAx3RWheel "前轴制动衬片剩余后轴3，右后轮";
CM_ SG_ 2633935883 BraLinRemainFrAxRWheel "前轴制动衬片剩余前轴，右前轮";
CM_ SG_ 2566767627 BrakeTemperatureWarn "制动温度报警（无效值，目前没用）";
CM_ SG_ 2566767627 XBRSystemState "XBR系统状态";
CM_ SG_ 2566767627 XBRActiveControlMode "XBR系统控制模式";
CM_ SG_ 2566767627 XBRAccelerationLimit "XBR加速度限制";
CM_ SG_ 2566767627 Haltbrakemode "停止制动模式（无用，客车用的）";
CM_ SG_ 2566767627 Hillholdermode "陡坡缓降模式（上坡辅助）";
CM_ SG_ 2566767627 FoundationBrakeUse "是否使用基础制动";
CM_ SG_ 2566803211 VDCLampState "VDC指示灯状态（车辆动态控制系统，ESP工作指示灯）";
CM_ SG_ 2566803211 ROPBrakeCrlactive "ROP制动控制使能（ESP也工作了，";
CM_ SG_ 2566803211 YCEngineCrlactive "YC发动机控制使能（ESP也工作了）";
CM_ SG_ 2566803211 YCBrakeCrlactive "YC制动控制使能（ESP也工作了）";
CM_ SG_ 2566803211 VDCFullyOperational "VDC是否全状态运行";
CM_ SG_ 2566803211 VDCbrakelightrequest "VDC是否要求点亮制动灯";
CM_ SG_ 2566803211 ROPEngineCrlactive "ROP发动机控制使能（ESP也工作了，）";
CM_ SG_ 2566838539 Auxiliary03 "停止制动模式（客车用，不发了）";
CM_ SG_ 2566838539 Auxiliary02 "请求制动灯（点亮制动灯）";
CM_ SG_ 2566838539 Auxiliary01 "制动辅助状态(主车制动帮助共功能)";
CM_ SG_ 2566838539 TrailerCrlPressure "拖车控制压力";
CM_ SG_ 2365484270 Tac_Output_Shaft_speed "轴转速输出信号";
CM_ SG_ 2365484270 Tac_VehicleSpeed "车速";
CM_ SG_ 2566832622 HighReTotalVehicleDistance "总计里程";
CM_ SG_ 2566832622 HighResolutionTripDistanceA "小计里程tripA";
CM_ SG_ 2566838551 CabinTiltSwitch "驾驶室锁止开关";
CM_ SG_ 2566838551 RetarderLeverPosition "RCM工作状态信号（仪表根据RCM_ERC1中的实际扭矩的报文，＜7D发1；≥7D发0）";
CM_ SG_ 2566838551 AverageSpeedA "小计里程平均车速 A";
CM_ SG_ 2566838551 TrailerBrakestatus "挂车制动状态 ";
CM_ SG_ 2566838551 AverageSpeedB "小计里程平均车速B";
CM_ SG_ 2566838551 OilChangedStatus "机油保养 重置状态 ";
CM_ SG_ 2566838551 Gearboxneutralposition "变速箱空档位置 ";
CM_ SG_ 2566848791 AlternatorChargingIndicatorLamp "蓄电池充电指示灯 ";
CM_ SG_ 2566848791 MainStatus "主题状态";
CM_ SG_ 2566848791 CurrentRunningComputer "当前使用的行车电脑";
CM_ SG_ 2566848791 AverageFuelEconomyB "小计里程平均油耗B";
CM_ SG_ 2566848791 SeatBeltIndicatorLamp "安全带未系提醒指示灯";
CM_ SG_ 2566848791 HighResolutionTripDistanceB "小计里程tripB";
CM_ SG_ 2566848791 GearHighLowStateTelltale "变速箱高/低档指示灯指示灯";
CM_ SG_ 2566848791 PTOIndicatorLamp "取力器指示灯";
CM_ SG_ 2566848791 TrailerABSIndicatorLamp "挂车ABS指示灯";
CM_ SG_ 2566805015 RemainingOilAuxiliaryTank "副油箱剩余油量";
CM_ SG_ 2566805015 UseOilBox "当前使用的油箱";
CM_ SG_ 2566805015 RemainingOilMainTank "主油箱剩余油量";
CM_ SG_ 2566849047 TSR_Main_SwitchIC "交通限速标指提醒开关";
CM_ SG_ 2566849047 NV_IntelligentSwitchC "NV功能开关";
CM_ SG_ 2566849047 LDW_SensitivityIC "LDW敏感级别";
CM_ SG_ 2566849047 FCW_Main_SwitchIC "前车碰撞报警开关";
CM_ SG_ 2566849047 DDWS_SwitchIC "DDWS开关";
CM_ SG_ 2566849047 OK_Switch "OK开关";
CM_ SG_ 2566849047 DDWS_SwitchICtwo "DDWS二三级开关";
CM_ SG_ 2566849047 FCW_SensitivityIC "前车碰撞报警敏感级别";
CM_ SG_ 2566849047 IHC_Main_SwitchIC "自动大灯开关";
CM_ SG_ 2565472279 ParameterGroupNumbeingrequested "请求PGN";
CM_ SG_ 2566844951 AverageFuelEconomyA "小计里程平均油耗 A";
CM_ SG_ 2566844951 DisplayTac_VehicleSpeed "仪表的显示车速";
CM_ SG_ 2561553175 Reference_Tire_Setting_Conmand "胎压学习指令";
CM_ SG_ 2566827543 ServiceBrakeAirPressureCircuit1 "行车制动气压，电路1(前桥制动气压数据；由于EBS功能严格按照1939实现，更改为回路1代表后桥制动)";
CM_ SG_ 2566827543 ServiceBrakeAirPressureCircuit2 "行车制动气压，电路2(后桥制动气压数据；由于EBS功能严格按照1939实现，更改为回路2代表前桥制动))";
CM_ SG_ 2566718743 EngineOilPressureLowLampData "发动机机油压力低灯状态";
CM_ SG_ 2566718743 EngCoolantTempHighLampData "发动机冷却液温度高灯状态 ";
CM_ SG_ 2566718743 EngineCoolantLevelLowLampData "发动机冷却液液位低灯状态";
CM_ SG_ 2566718743 EngAIRFilterRestrictLampData "发动机空气滤清器限制灯状态";
CM_ SG_ 2566718743 BrakeAirPressureLowCircuit2 "制动气压低回路2";
CM_ SG_ 2566718743 BrakeAirPressureLowCircuit1 "制动气压低回路1";
CM_ SG_ 2566718743 LowFuelLevelLampData "燃油液位低指示灯状态";
CM_ SG_ 2566718743 BatteryVoltage "蓄电池电压";
CM_ SG_ 2566718743 OBDMalfunctionIndicatorLampData "故障指示灯状态";
CM_ SG_ 2566718743 EngineBrakeActiveLampData "发动机制动灯状态（ECM的制动状态判断灯的状态给其他模块用）";
CM_ SG_ 2566847511 DistanceToempty2 "副油箱续航里程2";
CM_ SG_ 2566847511 CargoAmbientTemperatureIC "环境温度";
CM_ SG_ 2566847511 DistanceToempty1 "主油箱续航里程1";
CM_ SG_ 2566847511 FuelLevel "燃油液位";
CM_ BO_ 2566843415 "当数据场长度大于8个字节时按照J1939 TP层多包传输协议定义进行发送 IC_VIN_BAM 0x18ECFF17 IC_VIN_PACKET  0x18EBFF17";
CM_ SG_ 2566843415 VehicleIdentificationNumber1 " VIN(转换成ASCII码)";
CM_ SG_ 2566843415 DelimiterIC "定界符";
CM_ BO_ 2565668631 "VIN码多包传输的时候发";
CM_ BO_ 2565603095 "VIN码多包传输的时候发";
CM_ BO_ 2566904855 "有TBOX才发";
CM_ SG_ 2566904855 VehicleSpeedLimit "车辆速度限制";
CM_ SG_ 2566904855 EngineStartLimitStatus "发动机启动的限定状态 ";
CM_ SG_ 2566904855 EngineTorqueLimitStatus "发动机扭矩的限定状态 ";
CM_ SG_ 2566904855 VehicleSpeedLimitStatu "车辆速度的限定状态 ";
CM_ SG_ 2566904855 TorqueLimit "扭矩限制";
CM_ SG_ 2566909975 IC_NM_DA "IC网络管理报文目的地址";
CM_ SG_ 2566909975 IC_NM_Limphome "Limphome类型网络管理报文";
CM_ SG_ 2566909975 IC_NM_Sleep_Ind "睡眠指示";
CM_ SG_ 2566909975 IC_NM_Sleep_Ack "睡眠应答";
CM_ SG_ 2566909975 IC_NM_Alive "Alive类型网络管理报文";
CM_ SG_ 2566909975 IC_NM_Ring "Ring类型网络管理报文";
CM_ BO_ 2566834711 "默认发送数据见诊断规范定义,当数据场长度大于8个字节时按照J1939 TP层多包传输协议定义进行发送 DM1CLuster_BAM 0x1CECFF17 DM1CLuster_PACKET 0x1CEBFF17";
CM_ SG_ 2349541911 DriveractivationdemandforAdvance "先进紧急制动系统的驾驶员激活需求";
CM_ SG_ 2566842094 Seconds "秒";
CM_ SG_ 2566842094 Hours "小时";
CM_ SG_ 2566842094 Month "月";
CM_ SG_ 2566842094 Day "天";
CM_ SG_ 2566842094 Year "年";
CM_ SG_ 2566842094 LocalMinuteOffset "分钟偏移";
CM_ SG_ 2566842094 LocalHourOffset "小时偏移";
CM_ SG_ 2566842094 Minutes "分钟";
CM_ BO_ 2365526254 "当数据场长度大于8个字节时按照J1939 TP层多包传输协议定义进行发送TAC_DCNumber_BAM 0x18ECFF17 TAC_DCNumber_PACKET  0x18EBFF17";
CM_ SG_ 2365526254 DriverCardNumber "驾驶员卡号";
CM_ SG_ 2365526254 DriverCardState "驾驶员卡状态";
CM_ BO_ 2364342254 "TAC_DCNumber多包传输的时候发";
CM_ BO_ 2364276718 "TAC_DCNumber多包传输的时候发";
CM_ BO_ 2633943790 "默认发送数据见诊断规范定义,当数据场长度大于8个字节时按照J1939 TP层多包传输协议定义进行发送 DM1CLuster_BAM 0x1CECFFEE  DM1CLuster_PACKET 0x1CEBFFEE";
BA_DEF_ BO_  "NmMessage" ENUM  "No","Yes";
BA_DEF_ BO_  "DiagState" ENUM  "No","Yes";
BA_DEF_ BO_  "DiagResponse" ENUM  "No","Yes";
BA_DEF_ BO_  "GenMsgSendType" ENUM  "Cycle","NoSendType","IfActive","OnRequest";
BA_DEF_ BO_  "GenMsgCycleTime" INT 0 0;
BA_DEF_ SG_  "GenSigSendType" ENUM  "Cycle","OnChange","OnWrite","IfActive","OnChangeWithRepetition","OnWriteWithRepetition","IfActiveWithRepetition","NoSendType";
BA_DEF_ SG_  "GenSigStartValue" INT 0 0;
BA_DEF_ BO_  "GenMsgCycleTimeFast" INT 0 0;
BA_DEF_ BO_  "GenMsgNrOfRepetition" INT 0 0;
BA_DEF_  "DBName" STRING ;
BA_DEF_ SG_  "SPN" INT 0 0;
BA_DEF_ SG_  "SigType" ENUM  "Default","Range","RangeSigned","ASCII","Discrete","Control","ReferencePGN","DTC","StringDelimiter","StringLength","StringLengthControl";
BA_DEF_  "NMIdType" ENUM  "0: standard (11 bit, default)","1: extended (29 bit)";
BA_DEF_  "NmMessageCount" INT 0 256;
BA_DEF_ SG_  "GenSigEVName" STRING ;
BA_DEF_ SG_  "GenSigILSupport" ENUM  "Yes","No";
BA_DEF_ BO_  "GenMsgILSupport" ENUM  "Yes","No";
BA_DEF_ BO_  "GenMsgRequestable" INT 0 1;
BA_DEF_ BO_  "VFrameFormat" ENUM  "StandardCAN","ExtendedCAN","reserved","J1939PG";
BA_DEF_ BU_  "NodeLayerModules" STRING ;
BA_DEF_ BU_  "NmStationAddress" INT 0 255;
BA_DEF_  "ProtocolType" STRING ;
BA_DEF_ SG_  "SystemSignalLongSymbol" STRING ;
BA_DEF_DEF_  "NmMessage" "No";
BA_DEF_DEF_  "DiagState" "No";
BA_DEF_DEF_  "DiagResponse" "No";
BA_DEF_DEF_  "GenMsgSendType" "Cycle";
BA_DEF_DEF_  "GenMsgCycleTime" 0;
BA_DEF_DEF_  "GenSigSendType" "Cycle";
BA_DEF_DEF_  "GenSigStartValue" 0;
BA_DEF_DEF_  "GenMsgCycleTimeFast" 0;
BA_DEF_DEF_  "GenMsgNrOfRepetition" 0;
BA_DEF_DEF_  "DBName" "";
BA_DEF_DEF_  "SPN" 0;
BA_DEF_DEF_  "SigType" "Default";
BA_DEF_DEF_  "NMIdType" "0: standard (11 bit, default)";
BA_DEF_DEF_  "NmMessageCount" 128;
BA_DEF_DEF_  "GenSigEVName" "Env@Nodename_@Signame";
BA_DEF_DEF_  "GenSigILSupport" "Yes";
BA_DEF_DEF_  "GenMsgILSupport" "Yes";
BA_DEF_DEF_  "GenMsgRequestable" 1;
BA_DEF_DEF_  "VFrameFormat" "J1939PG";
BA_DEF_DEF_  "NodeLayerModules" "oseknm01.dll,CANoeILNLVector.dll,J1939_IL.dll";
BA_DEF_DEF_  "NmStationAddress" 254;
BA_DEF_DEF_  "ProtocolType" "J1939";
BA_DEF_DEF_  "SystemSignalLongSymbol" "";
BA_ "DBName" "BODCAN";
BA_ "NmStationAddress" BU_ BCM 33;
BA_ "NmStationAddress" BU_ TPMS 51;
BA_ "NmStationAddress" BU_ PEPS 52;
BA_ "NmStationAddress" BU_ IC 23;
BA_ "NmStationAddress" BU_ MP5 76;
BA_ "NmStationAddress" BU_ DDWS 231;
BA_ "NmStationAddress" BU_ NV 110;
BA_ "NmStationAddress" BU_ EATC 25;
BA_ "NmStationAddress" BU_ TAC 238;
BA_ "NmStationAddress" BU_ ESCL 77;
BA_ "NmStationAddress" BU_ GW 37;
BA_ "GenMsgCycleTime" BO_ 2566869068 500;
BA_ "GenMsgNrOfRepetition" BO_ 2566869324 2;
BA_ "GenMsgSendType" BO_ 2566869324 1;
BA_ "GenMsgNrOfRepetition" BO_ 2566869580 5;
BA_ "GenMsgCycleTimeFast" BO_ 2566869580 50;
BA_ "GenMsgSendType" BO_ 2566869580 1;
BA_ "GenMsgNrOfRepetition" BO_ 2566869836 5;
BA_ "GenMsgCycleTimeFast" BO_ 2566869836 50;
BA_ "GenMsgSendType" BO_ 2566869836 1;
BA_ "GenMsgCycleTime" BO_ 2566842444 1000;
BA_ "GenMsgNrOfRepetition" BO_ 2566870092 5;
BA_ "GenMsgCycleTimeFast" BO_ 2566870092 100;
BA_ "GenMsgSendType" BO_ 2566870092 1;
BA_ "GenMsgSendType" BO_ 2566910028 1;
BA_ "NmMessage" BO_ 2566910028 1;
BA_ "GenMsgCycleTime" BO_ 2566834764 1000;
BA_ "DiagResponse" BO_ 2566834764 1;
BA_ "DiagState" BO_ 2566834764 1;
BA_ "GenMsgCycleTime" BO_ 2566877415 100;
BA_ "GenMsgCycleTime" BO_ 2566877671 100;
BA_ "GenMsgCycleTime" BO_ 2566834919 1000;
BA_ "DiagResponse" BO_ 2566834919 1;
BA_ "DiagState" BO_ 2566834919 1;
BA_ "GenMsgCycleTime" BO_ 2566889497 50;
BA_ "GenMsgCycleTime" BO_ 2566841377 1000;
BA_ "GenMsgSendType" BO_ 2566909977 1;
BA_ "NmMessage" BO_ 2566909977 1;
BA_ "GenMsgCycleTime" BO_ 2566834713 1000;
BA_ "DiagResponse" BO_ 2566834713 1;
BA_ "DiagState" BO_ 2566834713 1;
BA_ "GenMsgCycleTime" BO_ 2566843904 1000;
BA_ "GenMsgCycleTime" BO_ 2566844672 100;
BA_ "GenMsgCycleTime" BO_ 2364539648 50;
BA_ "GenMsgCycleTime" BO_ 2364539904 10;
BA_ "GenMsgSendType" BO_ 2566841600 1;
BA_ "GenMsgCycleTime" BO_ 2566844928 100;
BA_ "GenMsgCycleTime" BO_ 2565865487 100;
BA_ "GenMsgCycleTime" BO_ 2566719744 1000;
BA_ "GenMsgSendType" BO_ 2566842112 1;
BA_ "GenMsgCycleTime" BO_ 2566804992 1000;
BA_ "GenMsgCycleTime" BO_ 2566841344 1000;
BA_ "GenMsgCycleTime" BO_ 2566848256 1000;
BA_ "GenMsgCycleTime" BO_ 2566754816 250;
BA_ "GenMsgCycleTime" BO_ 2566843648 1000;
BA_ "GenMsgCycleTime" BO_ 2566834688 1000;
BA_ "DiagResponse" BO_ 2566834688 1;
BA_ "DiagState" BO_ 2566834688 1;
BA_ "GenMsgSendType" BO_ 2565668608 1;
BA_ "DiagResponse" BO_ 2565668608 1;
BA_ "DiagState" BO_ 2565668608 1;
BA_ "GenMsgSendType" BO_ 2565603072 1;
BA_ "DiagResponse" BO_ 2565603072 1;
BA_ "DiagState" BO_ 2565603072 1;
BA_ "GenMsgCycleTime" BO_ 2566852608 50;
BA_ "GenMsgSendType" BO_ 2566852864 1;
BA_ "GenMsgCycleTime" BO_ 2566775040 1000;
BA_ "GenMsgCycleTime" BO_ 2566749184 1000;
BA_ "GenMsgCycleTime" BO_ 2566849024 1000;
BA_ "GenMsgCycleTime" BO_ 2565865739 100;
BA_ "GenMsgCycleTime" BO_ 2566834699 1000;
BA_ "DiagResponse" BO_ 2566834699 1;
BA_ "DiagState" BO_ 2566834699 1;
BA_ "GenMsgSendType" BO_ 2565668619 1;
BA_ "DiagResponse" BO_ 2565668619 1;
BA_ "DiagState" BO_ 2565668619 1;
BA_ "GenMsgSendType" BO_ 2565603083 1;
BA_ "DiagResponse" BO_ 2565603083 1;
BA_ "DiagState" BO_ 2565603083 1;
BA_ "GenMsgCycleTime" BO_ 2633935883 5000;
BA_ "GenMsgCycleTime" BO_ 2566767627 100;
BA_ "GenMsgCycleTime" BO_ 2566803211 100;
BA_ "GenMsgCycleTime" BO_ 2566838539 100;
BA_ "GenMsgCycleTime" BO_ 2365484270 50;
BA_ "GenMsgCycleTime" BO_ 2566832622 1000;
BA_ "GenMsgCycleTime" BO_ 2566838551 100;
BA_ "GenMsgCycleTime" BO_ 2566848791 100;
BA_ "GenMsgCycleTime" BO_ 2566805015 1000;
BA_ "GenMsgNrOfRepetition" BO_ 2566849047 5;
BA_ "GenMsgCycleTimeFast" BO_ 2566849047 100;
BA_ "GenMsgSendType" BO_ 2566849047 1;
BA_ "GenMsgCycleTime" BO_ 2565472279 1000;
BA_ "GenMsgCycleTime" BO_ 2566844951 100;
BA_ "GenMsgCycleTime" BO_ 2561553175 500;
BA_ "GenMsgCycleTime" BO_ 2566827543 1000;
BA_ "GenMsgCycleTime" BO_ 2566718743 1000;
BA_ "GenMsgCycleTime" BO_ 2566847511 1000;
BA_ "GenMsgCycleTimeFast" BO_ 2566843415 1000;
BA_ "GenMsgSendType" BO_ 2566843415 1;
BA_ "GenMsgSendType" BO_ 2565668631 1;
BA_ "DiagResponse" BO_ 2565668631 1;
BA_ "DiagState" BO_ 2565668631 1;
BA_ "GenMsgSendType" BO_ 2565603095 1;
BA_ "DiagResponse" BO_ 2565603095 1;
BA_ "DiagState" BO_ 2565603095 1;
BA_ "GenMsgCycleTimeFast" BO_ 2566904855 1000;
BA_ "GenMsgSendType" BO_ 2566904855 2;
BA_ "GenMsgCycleTime" BO_ 2566909975 100;
BA_ "NmMessage" BO_ 2566909975 1;
BA_ "GenMsgCycleTime" BO_ 2566834711 1000;
BA_ "DiagResponse" BO_ 2566834711 1;
BA_ "DiagState" BO_ 2566834711 1;
BA_ "GenMsgCycleTime" BO_ 2349541911 50;
BA_ "GenMsgCycleTime" BO_ 2566842094 1000;
BA_ "GenMsgCycleTimeFast" BO_ 2365526254 1000;
BA_ "GenMsgSendType" BO_ 2365526254 1;
BA_ "GenMsgSendType" BO_ 2364342254 1;
BA_ "DiagResponse" BO_ 2364342254 1;
BA_ "DiagState" BO_ 2364342254 1;
BA_ "GenMsgSendType" BO_ 2364276718 1;
BA_ "DiagResponse" BO_ 2364276718 1;
BA_ "DiagState" BO_ 2364276718 1;
BA_ "GenMsgCycleTime" BO_ 2633943790 1000;
BA_ "DiagResponse" BO_ 2633943790 1;
BA_ "DiagState" BO_ 2633943790 1;
BA_ "SPN" SG_ 2566869068 FMRadioChanel 520964;
BA_ "SPN" SG_ 2566869068 USBConnectionStatus 520966;
BA_ "SPN" SG_ 2566869068 BluetoothConnectionStatus 520967;
BA_ "SPN" SG_ 2566869068 FM_AM_MUSICStatus 521021;
BA_ "GenSigStartValue" SG_ 2566869068 FM_AM_MUSICStatus 1;
BA_ "SPN" SG_ 2566869068 PhoneStatus 521022;
BA_ "GenSigStartValue" SG_ 2566869068 PhoneStatus 1;
BA_ "SPN" SG_ 2566869068 VehicleDirectionStatus 521023;
BA_ "GenSigStartValue" SG_ 2566869068 VehicleDirectionStatus 1;
BA_ "SPN" SG_ 2566869068 AMRadioChanel 520965;
BA_ "SPN" SG_ 2566869324 EHC5_St_FrameType 520968;
BA_ "GenSigSendType" SG_ 2566869324 EHC5_St_FrameType 1;
BA_ "SPN" SG_ 2566869580 PhoneNumInternational1 520969;
BA_ "GenSigSendType" SG_ 2566869580 PhoneNumInternational1 4;
BA_ "SPN" SG_ 2566869580 PhoneNumInternational4 520972;
BA_ "GenSigSendType" SG_ 2566869580 PhoneNumInternational4 4;
BA_ "SPN" SG_ 2566869580 PhoneNum1 520973;
BA_ "GenSigSendType" SG_ 2566869580 PhoneNum1 4;
BA_ "SPN" SG_ 2566869580 PhoneNum2 520974;
BA_ "GenSigSendType" SG_ 2566869580 PhoneNum2 4;
BA_ "SPN" SG_ 2566869580 PhoneNum3 520975;
BA_ "GenSigSendType" SG_ 2566869580 PhoneNum3 4;
BA_ "SPN" SG_ 2566869580 PhoneNum4 520976;
BA_ "GenSigSendType" SG_ 2566869580 PhoneNum4 4;
BA_ "SPN" SG_ 2566869580 PhoneNum5 520977;
BA_ "GenSigSendType" SG_ 2566869580 PhoneNum5 4;
BA_ "SPN" SG_ 2566869580 PhoneNum6 520978;
BA_ "GenSigSendType" SG_ 2566869580 PhoneNum6 4;
BA_ "SPN" SG_ 2566869580 PhoneNumInternational2 520970;
BA_ "GenSigSendType" SG_ 2566869580 PhoneNumInternational2 4;
BA_ "SPN" SG_ 2566869580 PhoneNum7 520979;
BA_ "GenSigSendType" SG_ 2566869580 PhoneNum7 4;
BA_ "SPN" SG_ 2566869580 PhoneNum8 520980;
BA_ "GenSigSendType" SG_ 2566869580 PhoneNum8 4;
BA_ "SPN" SG_ 2566869580 PhoneNum9 520981;
BA_ "GenSigSendType" SG_ 2566869580 PhoneNum9 4;
BA_ "SPN" SG_ 2566869580 PhoneNum10 520982;
BA_ "GenSigSendType" SG_ 2566869580 PhoneNum10 4;
BA_ "SPN" SG_ 2566869580 PhoneNum11 520983;
BA_ "GenSigSendType" SG_ 2566869580 PhoneNum11 4;
BA_ "SPN" SG_ 2566869580 PhoneNum12 520984;
BA_ "GenSigSendType" SG_ 2566869580 PhoneNum12 4;
BA_ "SPN" SG_ 2566869580 PhoneNumInternational3 520971;
BA_ "GenSigSendType" SG_ 2566869580 PhoneNumInternational3 4;
BA_ "SPN" SG_ 2566869836 Volume_AddorSubtract 520985;
BA_ "GenSigSendType" SG_ 2566869836 Volume_AddorSubtract 4;
BA_ "SPN" SG_ 2566869836 AUTO_switch 520991;
BA_ "GenSigSendType" SG_ 2566869836 AUTO_switch 4;
BA_ "SPN" SG_ 2566869836 OFF_switch 520992;
BA_ "GenSigSendType" SG_ 2566869836 OFF_switch 4;
BA_ "SPN" SG_ 2566869836 Temp_AddorSubtract 520986;
BA_ "GenSigSendType" SG_ 2566869836 Temp_AddorSubtract 4;
BA_ "SPN" SG_ 2566869836 Recurrent_Switch 520993;
BA_ "GenSigSendType" SG_ 2566869836 Recurrent_Switch 4;
BA_ "SPN" SG_ 2566869836 Acswitch 520987;
BA_ "GenSigSendType" SG_ 2566869836 Acswitch 4;
BA_ "SPN" SG_ 2566869836 MAX_Acswitch 521017;
BA_ "GenSigSendType" SG_ 2566869836 MAX_Acswitch 4;
BA_ "SPN" SG_ 2566869836 ModelSwitch 520988;
BA_ "GenSigSendType" SG_ 2566869836 ModelSwitch 4;
BA_ "SPN" SG_ 2566842444 VehicleDirection 165;
BA_ "SPN" SG_ 2566842444 NAV_TurnWaringDistce 520997;
BA_ "GenSigSendType" SG_ 2566842444 NAV_TurnWaringDistce 4;
BA_ "SPN" SG_ 2566842444 NAV_DesDistce 520998;
BA_ "GenSigSendType" SG_ 2566842444 NAV_DesDistce 4;
BA_ "SPN" SG_ 2566842444 NAV_DepartureWaring 521001;
BA_ "GenSigSendType" SG_ 2566842444 NAV_DepartureWaring 4;
BA_ "SPN" SG_ 2566842444 NAV_DesTime 521002;
BA_ "GenSigSendType" SG_ 2566842444 NAV_DesTime 4;
BA_ "SPN" SG_ 2566842444 NAV_TurnWaring 520999;
BA_ "GenSigSendType" SG_ 2566842444 NAV_TurnWaring 4;
BA_ "SPN" SG_ 2566870092 TSR_Main_Switch 520331;
BA_ "GenSigSendType" SG_ 2566870092 TSR_Main_Switch 4;
BA_ "SPN" SG_ 2566870092 LDW_Sensitivity 520354;
BA_ "GenSigSendType" SG_ 2566870092 LDW_Sensitivity 4;
BA_ "SPN" SG_ 2566870092 FCW_Main_Switch 520328;
BA_ "GenSigSendType" SG_ 2566870092 FCW_Main_Switch 4;
BA_ "SPN" SG_ 2566870092 DDWS_SwitchOne 520360;
BA_ "GenSigSendType" SG_ 2566870092 DDWS_SwitchOne 4;
BA_ "GenSigSendType" SG_ 2566870092 DDWS_SwitchTwo 4;
BA_ "SPN" SG_ 2566870092 FCW_Sensitivity 520329;
BA_ "GenSigSendType" SG_ 2566870092 FCW_Sensitivity 4;
BA_ "SPN" SG_ 2566870092 IHC_Main_Switch 520330;
BA_ "GenSigSendType" SG_ 2566870092 IHC_Main_Switch 4;
BA_ "SPN" SG_ 2566910028 MP5_NM_DA 521010;
BA_ "GenSigSendType" SG_ 2566910028 MP5_NM_DA 2;
BA_ "SPN" SG_ 2566910028 MP5_NM_Limphome 521013;
BA_ "GenSigSendType" SG_ 2566910028 MP5_NM_Limphome 2;
BA_ "SPN" SG_ 2566910028 MP5_NM_Sleep_Ind 521014;
BA_ "GenSigSendType" SG_ 2566910028 MP5_NM_Sleep_Ind 2;
BA_ "SPN" SG_ 2566910028 MP5_NM_Sleep_Ack 521015;
BA_ "GenSigSendType" SG_ 2566910028 MP5_NM_Sleep_Ack 2;
BA_ "SPN" SG_ 2566910028 MP5_NM_Alive 521011;
BA_ "GenSigSendType" SG_ 2566910028 MP5_NM_Alive 2;
BA_ "SPN" SG_ 2566910028 MP5_NM_Ring 521012;
BA_ "GenSigSendType" SG_ 2566910028 MP5_NM_Ring 2;
BA_ "SPN" SG_ 2566877415 Eyes_closed_level1_alarm 521216;
BA_ "SPN" SG_ 2566877415 Yawned 521218;
BA_ "SPN" SG_ 2566877415 Distraction 521219;
BA_ "SPN" SG_ 2566877415 CallPhone 521220;
BA_ "SPN" SG_ 2566877415 SmokingWarning 521221;
BA_ "SPN" SG_ 2566877415 WarningStatus 521222;
BA_ "SPN" SG_ 2566877415 WorkingState 521225;
BA_ "SPN" SG_ 2566877415 Eyes_closed_level2_alarm 521217;
BA_ "SPN" SG_ 2566877671 Eyes_closed_Time 521223;
BA_ "SPN" SG_ 2566889497 ACReq 521600;
BA_ "SPN" SG_ 2566889497 Model_state 521606;
BA_ "SPN" SG_ 2566889497 BlowerLvlStatus 521607;
BA_ "SPN" SG_ 2566889497 MaxACReq 521601;
BA_ "SPN" SG_ 2566889497 Temp_Set 521609;
BA_ "SPN" SG_ 2566889497 CompressorOpeningStates 521610;
BA_ "SPN" SG_ 2566889497 DiagnosticEATC 521611;
BA_ "SPN" SG_ 2566889497 HeaterMirror_switch 521602;
BA_ "SPN" SG_ 2566889497 Recurrent_State 521612;
BA_ "SPN" SG_ 2566889497 AUTO_state 521603;
BA_ "SPN" SG_ 2566889497 OFF_state 521604;
BA_ "SPN" SG_ 2566841377 A_C_CompressorSwitch 521600;
BA_ "SPN" SG_ 2566909977 EATC_NM_DA 521010;
BA_ "GenSigSendType" SG_ 2566909977 EATC_NM_DA 2;
BA_ "SPN" SG_ 2566909977 EATC_NM_Limphome 521013;
BA_ "GenSigSendType" SG_ 2566909977 EATC_NM_Limphome 2;
BA_ "SPN" SG_ 2566909977 EATC_NM_Sleep_Ind 521014;
BA_ "GenSigSendType" SG_ 2566909977 EATC_NM_Sleep_Ind 2;
BA_ "SPN" SG_ 2566909977 EATC_NM_Sleep_Ack 521015;
BA_ "GenSigSendType" SG_ 2566909977 EATC_NM_Sleep_Ack 2;
BA_ "SPN" SG_ 2566909977 EATC_NM_Alive 521011;
BA_ "GenSigSendType" SG_ 2566909977 EATC_NM_Alive 2;
BA_ "SPN" SG_ 2566909977 EATC_NM_Ring 521012;
BA_ "GenSigSendType" SG_ 2566909977 EATC_NM_Ring 2;
BA_ "SPN" SG_ 2566843904 Engine_coolant_temperature 110;
BA_ "SPN" SG_ 2566843904 EngineOilTemperature1 175;
BA_ "SPN" SG_ 2566843904 FuelTemperature 174;
BA_ "SPN" SG_ 2566844672 Two_speed_axle_switch 69;
BA_ "SPN" SG_ 2566844672 Parking_brake_switch 70;
BA_ "SPN" SG_ 2566844672 Cruise_Control_active 595;
BA_ "SPN" SG_ 2566844672 Cruise_Control_enable_switch 596;
BA_ "SPN" SG_ 2566844672 Status_of_brake_switch 597;
BA_ "SPN" SG_ 2566844672 Status_of_clutch_switch 598;
BA_ "SPN" SG_ 2566844672 Cruise_Control_set_switch 599;
BA_ "SPN" SG_ 2566844672 Cruise_Control_coast_switch 600;
BA_ "SPN" SG_ 2566844672 Cruise_Control_resume_switch 601;
BA_ "SPN" SG_ 2566844672 Cruise_Control_accelerate_switch 602;
BA_ "SPN" SG_ 2566844672 Charge_Mode 1633;
BA_ "SPN" SG_ 2566844672 Cruise_Control_set_speed 86;
BA_ "SPN" SG_ 2566844672 PTO_state 976;
BA_ "SPN" SG_ 2566844672 Cruise_Control_state 527;
BA_ "SPN" SG_ 2566844672 IdleIncrementSwitch 968;
BA_ "SPN" SG_ 2566844672 IdleDecrementSwitch 967;
BA_ "SPN" SG_ 2566844672 EngineTestModeSwitch 966;
BA_ "SPN" SG_ 2566844672 Engine_shutdown_override_switch 1237;
BA_ "SPN" SG_ 2566844672 Wheel_based_vehicle_speed 84;
BA_ "SPN" SG_ 2364539648 AcceleratorPedal1LowIdleSwitch 558;
BA_ "SPN" SG_ 2364539648 EnginePercentLoadAtCurrentSpeed 92;
BA_ "SPN" SG_ 2364539648 AcceleratorPedalKickdownSwitch 559;
BA_ "SPN" SG_ 2364539648 RemoteAccelerator 974;
BA_ "SPN" SG_ 2364539648 AcceleratorPedalPosition2 29;
BA_ "SPN" SG_ 2364539648 RoadSpeedLimitStatus 1437;
BA_ "SPN" SG_ 2364539648 VehicleAccelRateLmtStatus 2979;
BA_ "SPN" SG_ 2364539648 ActuMaxAvailableEngPcntTorque 3357;
BA_ "SPN" SG_ 2364539648 GearShiftIndication 2970;
BA_ "SPN" SG_ 2364539648 AcceleratorPedalPosition1 91;
BA_ "SPN" SG_ 2364539904 EngineTorqueMode 899;
BA_ "SPN" SG_ 2364539904 ActualEnginePercentTorque 513;
BA_ "SPN" SG_ 2364539904 EngineSpeed 190;
BA_ "SPN" SG_ 2364539904 ActualEnginePercentTorque_Fracti 4154;
BA_ "SystemSignalLongSymbol" SG_ 2364539904 ActualEnginePercentTorque_Fracti "ActualEnginePercentTorque_Fractional";
BA_ "SPN" SG_ 2364539904 SourceAddofCtrlDeviceforEngCtrl 1483;
BA_ "SPN" SG_ 2364539904 EngineStarterMode 1675;
BA_ "SPN" SG_ 2364539904 EngineDemandPercentTorque 2432;
BA_ "SPN" SG_ 2364539904 DriverDemandEnginePercentTorque 512;
BA_ "SPN" SG_ 2566841600 TotalEngineHours 247;
BA_ "GenSigSendType" SG_ 2566841600 TotalEngineHours 4;
BA_ "SPN" SG_ 2566841600 TotalEngineRevolutions 249;
BA_ "GenSigSendType" SG_ 2566841600 TotalEngineRevolutions 4;
BA_ "SPN" SG_ 2566844928 FuelRate 183;
BA_ "SPN" SG_ 2566844928 InstantaneousFuelEconomy 184;
BA_ "SPN" SG_ 2566844928 AverageFuelEconomy 185;
BA_ "SPN" SG_ 2566844928 EngineThrottlePosition 51;
BA_ "SPN" SG_ 2566844928 EngineThrottle2Position 3673;
BA_ "SPN" SG_ 2565865487 RetarderTorqueMode 900;
BA_ "SPN" SG_ 2565865487 IntendedRetarderPercentTorque 1085;
BA_ "SPN" SG_ 2565865487 EngineCoolantLoadIncrease 1082;
BA_ "SPN" SG_ 2565865487 RetarderRequestingBrakeLight 1667;
BA_ "SPN" SG_ 2565865487 SrcAddOfCtrlDeviceRetarderCtrl 1480;
BA_ "SPN" SG_ 2565865487 RetarderEnableBrakeAssistSwitch 571;
BA_ "SPN" SG_ 2565865487 DrvrDemandRetarderPcntTorque 1715;
BA_ "SPN" SG_ 2565865487 RetarderSelectionNonEngine 1716;
BA_ "SPN" SG_ 2565865487 ActuMaxAvailRetarderPcntTorque 1717;
BA_ "SPN" SG_ 2565865487 RetarderEnableShiftAssistSwitch 572;
BA_ "SPN" SG_ 2565865487 ActualRetarderPercentTorque 520;
BA_ "SPN" SG_ 2566719744 HighResolutionEngineTripFuel 5053;
BA_ "SPN" SG_ 2566719744 HighResolutionEngTotalFuelUsed 5054;
BA_ "SPN" SG_ 2566842112 TotalVehicleHours 246;
BA_ "GenSigSendType" SG_ 2566842112 TotalVehicleHours 4;
BA_ "SPN" SG_ 2566842112 TotalPowerTakeOffHours 248;
BA_ "GenSigSendType" SG_ 2566842112 TotalPowerTakeOffHours 4;
BA_ "SPN" SG_ 2566804992 CatalystTankLevel 1761;
BA_ "SPN" SG_ 2566804992 SCRSpecMsgAdBlueUreaWarnLvlChain 5245;
BA_ "SPN" SG_ 2566804992 SCRSpecificMessagesAdBlueQuality 5246;
BA_ "SPN" SG_ 2566804992 CatalystTankTemperature 3031;
BA_ "SPN" SG_ 2566841344 IdleShutdownHasShutdownEngine 593;
BA_ "SPN" SG_ 2566841344 IdleShutdownTimerFunction 591;
BA_ "SPN" SG_ 2566841344 A_CHighPressureFanSwitch 985;
BA_ "SPN" SG_ 2566841344 RefrigerantLowPressureSwitch 875;
BA_ "SPN" SG_ 2566841344 EngIdleShutdownDriverAlertMode 594;
BA_ "SPN" SG_ 2566841344 RefrigerantHighPressureSwitch 605;
BA_ "SPN" SG_ 2566841344 WaitToStartLamp 1081;
BA_ "SPN" SG_ 2566841344 EngProtectSystemHasShutdownEng 1110;
BA_ "SPN" SG_ 2566841344 EngProtectSystemApproachShutdown 1109;
BA_ "SPN" SG_ 2566841344 EngProtectionSystemTimerOverride 1108;
BA_ "SPN" SG_ 2566841344 EngineProtectionSystemTimerState 1107;
BA_ "SPN" SG_ 2566841344 IdleShutdownTimerOverride 592;
BA_ "SPN" SG_ 2566841344 EngProtectionSystemConfig 1111;
BA_ "SPN" SG_ 2566841344 EngineAlarmAcknowledge 2815;
BA_ "SPN" SG_ 2566841344 EngineAlarmOutputCommandStatus 2814;
BA_ "SPN" SG_ 2566841344 EngineAirShutoffCommandStatus 2813;
BA_ "SPN" SG_ 2566841344 EngineOverspeedTest 2812;
BA_ "SPN" SG_ 2566841344 EngineAirShutoffStatus 3667;
BA_ "SPN" SG_ 2566841344 IdleShutdownTimerState 590;
BA_ "SPN" SG_ 2566848256 WaterInFuelIndicator 97;
BA_ "SPN" SG_ 2566848256 SCRSpecificMessagesTampering 5826;
BA_ "SPN" SG_ 2566848256 SCRSpecificMessagesAdblue 5825;
BA_ "SPN" SG_ 2566754816 EngineOperatingState 3543;
BA_ "GenSigSendType" SG_ 2566852864 ChallengeFrame_EMS0 2;
BA_ "GenSigSendType" SG_ 2566852864 ChallengeFrame_EMS2 2;
BA_ "GenSigSendType" SG_ 2566852864 ChallengeFrame_EMS3 2;
BA_ "GenSigSendType" SG_ 2566852864 ChallengeFrame_EMS4 2;
BA_ "GenSigSendType" SG_ 2566852864 ChallengeFrame_EMS5 2;
BA_ "GenSigSendType" SG_ 2566852864 ChallengeFrame_EMS6 2;
BA_ "GenSigSendType" SG_ 2566852864 ChallengeFrame_EMS7 2;
BA_ "GenSigSendType" SG_ 2566852864 ChallengeFrame_EMS1 2;
BA_ "SystemSignalLongSymbol" SG_ 2566775040 CabA_CRefrigerantCompressorOutle "CabA_CRefrigerantCompressorOutletPressure";
BA_ "SPN" SG_ 2566749184 Diesel_Particulate_Filter_Status 3701;
BA_ "SPN" SG_ 2566749184 ECM_DPF_ActRegInhSw 3703;
BA_ "SPN" SG_ 2566749184 ECM_DPF_ActRegInhsysflt 3712;
BA_ "SPN" SG_ 2566749184 ECM_ExstSysHTemLampComm 3698;
BA_ "SPN" SG_ 2565865739 ATCEngineControlActive 561;
BA_ "SPN" SG_ 2565865739 ABSoff_roadswitch 575;
BA_ "SPN" SG_ 2565865739 ATCoff_roadswitch 576;
BA_ "SPN" SG_ 2565865739 ATCBrakeControlActive 562;
BA_ "SPN" SG_ 2565865739 ASRHillHolderSwitch 577;
BA_ "SPN" SG_ 2565865739 TractionControlOverrideSwitch 1238;
BA_ "SPN" SG_ 2565865739 AcceleratorInterlockSwitch 972;
BA_ "SPN" SG_ 2565865739 EngineDerateSwitch 971;
BA_ "SPN" SG_ 2565865739 EngineAuxiliaryShutdownSwitch 970;
BA_ "SPN" SG_ 2565865739 RemoteAcceleratorEnableSwitch 969;
BA_ "SPN" SG_ 2565865739 EngineRetarderSelection 973;
BA_ "SPN" SG_ 2565865739 ABSActive 563;
BA_ "SPN" SG_ 2565865739 ABSfullyOperational 1243;
BA_ "SPN" SG_ 2565865739 EBSRedWarningSignal 1439;
BA_ "SPN" SG_ 2565865739 ABS_EBSamberWarningState 1438;
BA_ "SPN" SG_ 2565865739 ATCLampState 1793;
BA_ "SPN" SG_ 2565865739 SourceAddressofControllingDevice 1481;
BA_ "SystemSignalLongSymbol" SG_ 2565865739 SourceAddressofControllingDevice "SourceAddressofControllingDeviceforBrakeControl";
BA_ "SPN" SG_ 2565865739 EBSBrakeSwitch 1121;
BA_ "SPN" SG_ 2565865739 BrakePedalPosition 521;
BA_ "SPN" SG_ 2566834699 ProtectLampStateABS 987;
BA_ "SPN" SG_ 2566834699 SPN8leastSignificantBitOfSPNABS 1214;
BA_ "SPN" SG_ 2566834699 AmberWarningLampStatusABS 624;
BA_ "SPN" SG_ 2566834699 SPNSecondByteABS 1214;
BA_ "SPN" SG_ 2566834699 FMIABS 1215;
BA_ "SPN" SG_ 2566834699 SPN3MostSignificantBitABS 1214;
BA_ "SPN" SG_ 2566834699 RedStopLampZStatusABS 623;
BA_ "SPN" SG_ 2566834699 OccurrenceCountABS 1216;
BA_ "SPN" SG_ 2566834699 SPNConversionMethodABS 1706;
BA_ "SPN" SG_ 2566834699 MalfunctionIndicatorLampStatusAB 1213;
BA_ "SystemSignalLongSymbol" SG_ 2566834699 MalfunctionIndicatorLampStatusAB "MalfunctionIndicatorLampStatusABS";
BA_ "SPN" SG_ 2633935883 BraLinRemainFrAxleLWheel 1099;
BA_ "SPN" SG_ 2633935883 BraLinRemainRearAx1LWheel 1101;
BA_ "SPN" SG_ 2633935883 BraLinRemainRearAx1RWheel 1102;
BA_ "SPN" SG_ 2633935883 BraLinRemainRearAx2LWheel 1103;
BA_ "SPN" SG_ 2633935883 BraLinRemainRearAx2RWheel 1104;
BA_ "SPN" SG_ 2633935883 BraLinRemainRearAx3LWheel 1105;
BA_ "SPN" SG_ 2633935883 BraLinRemainRearAx3RWheel 1106;
BA_ "SPN" SG_ 2633935883 BraLinRemainFrAxRWheel 1100;
BA_ "SPN" SG_ 2566767627 BrakeTemperatureWarn 3839;
BA_ "SPN" SG_ 2566767627 XBRSystemState 2917;
BA_ "SPN" SG_ 2566767627 XBRActiveControlMode 2918;
BA_ "SPN" SG_ 2566767627 XBRAccelerationLimit 2921;
BA_ "SPN" SG_ 2566767627 Haltbrakemode 2913;
BA_ "SPN" SG_ 2566767627 Hillholdermode 2912;
BA_ "SPN" SG_ 2566767627 FoundationBrakeUse 2919;
BA_ "SPN" SG_ 2566803211 VDCLampState 1813;
BA_ "SPN" SG_ 2566803211 ROPBrakeCrlactive 1818;
BA_ "SPN" SG_ 2566803211 YCEngineCrlactive 1817;
BA_ "SPN" SG_ 2566803211 YCBrakeCrlactive 1819;
BA_ "SPN" SG_ 2566803211 VDCFullyOperational 1814;
BA_ "SPN" SG_ 2566803211 VDCbrakelightrequest 1815;
BA_ "SPN" SG_ 2566803211 ROPEngineCrlactive 1816;
BA_ "SPN" SG_ 2566838539 Auxiliary08 708;
BA_ "SPN" SG_ 2566838539 Auxiliary07 707;
BA_ "SPN" SG_ 2566838539 Auxiliary03 704;
BA_ "SPN" SG_ 2566838539 Auxiliary06 706;
BA_ "SPN" SG_ 2566838539 Auxiliary05 705;
BA_ "SPN" SG_ 2566838539 Auxiliary09 709;
BA_ "SPN" SG_ 2566838539 Auxiliary02 704;
BA_ "SPN" SG_ 2566838539 Auxiliary01 704;
BA_ "SPN" SG_ 2365484270 Tac_Output_Shaft_speed 1623;
BA_ "SPN" SG_ 2365484270 Tac_VehicleSpeed 1624;
BA_ "SPN" SG_ 2566832622 HighReTotalVehicleDistance 917;
BA_ "SPN" SG_ 2566832622 HighResolutionTripDistanceA 918;
BA_ "SPN" SG_ 2566838551 CabinTiltSwitch 712;
BA_ "SPN" SG_ 2566838551 RetarderLeverPosition 703;
BA_ "SPN" SG_ 2566838551 AverageSpeedA 1083;
BA_ "SPN" SG_ 2566838551 TrailerBrakestatus 702;
BA_ "SPN" SG_ 2566838551 AverageSpeedB 1084;
BA_ "SPN" SG_ 2566838551 OilChangedStatus 701;
BA_ "SPN" SG_ 2566838551 Gearboxneutralposition 708;
BA_ "SPN" SG_ 2566848791 AlternatorChargingIndicatorLamp 520323;
BA_ "SPN" SG_ 2566848791 MainStatus 520364;
BA_ "SPN" SG_ 2566848791 AverageFuelEconomyB 520320;
BA_ "SPN" SG_ 2566848791 SeatBeltIndicatorLamp 520324;
BA_ "SPN" SG_ 2566848791 HighResolutionTripDistanceB 520328;
BA_ "SPN" SG_ 2566848791 GearHighLowStateTelltale 520325;
BA_ "SPN" SG_ 2566848791 PTOIndicatorLamp 520326;
BA_ "SPN" SG_ 2566848791 TrailerABSIndicatorLamp 520327;
BA_ "SPN" SG_ 2566805015 RemainingOilAuxiliaryTank 520357;
BA_ "SPN" SG_ 2566805015 UseOilBox 520363;
BA_ "SPN" SG_ 2566805015 RemainingOilMainTank 520356;
BA_ "SPN" SG_ 2566849047 TSR_Main_SwitchIC 520331;
BA_ "GenSigSendType" SG_ 2566849047 TSR_Main_SwitchIC 1;
BA_ "SPN" SG_ 2566849047 NV_IntelligentSwitchC 520365;
BA_ "GenSigSendType" SG_ 2566849047 NV_IntelligentSwitchC 1;
BA_ "SPN" SG_ 2566849047 LDW_SensitivityIC 520354;
BA_ "GenSigSendType" SG_ 2566849047 LDW_SensitivityIC 1;
BA_ "SPN" SG_ 2566849047 FCW_Main_SwitchIC 520328;
BA_ "GenSigSendType" SG_ 2566849047 FCW_Main_SwitchIC 1;
BA_ "SPN" SG_ 2566849047 DDWS_SwitchIC 520360;
BA_ "GenSigSendType" SG_ 2566849047 DDWS_SwitchIC 1;
BA_ "SPN" SG_ 2566849047 OK_Switch 520361;
BA_ "GenSigSendType" SG_ 2566849047 OK_Switch 1;
BA_ "SPN" SG_ 2566849047 DDWS_SwitchICtwo 520360;
BA_ "GenSigSendType" SG_ 2566849047 DDWS_SwitchICtwo 4;
BA_ "SPN" SG_ 2566849047 FCW_SensitivityIC 520329;
BA_ "GenSigSendType" SG_ 2566849047 FCW_SensitivityIC 1;
BA_ "SPN" SG_ 2566849047 IHC_Main_SwitchIC 520330;
BA_ "GenSigSendType" SG_ 2566849047 IHC_Main_SwitchIC 1;
BA_ "SPN" SG_ 2565472279 ParameterGroupNumbeingrequested 520333;
BA_ "SPN" SG_ 2566844951 AverageFuelEconomyA 185;
BA_ "SPN" SG_ 2566844951 DisplayTac_VehicleSpeed 520355;
BA_ "SPN" SG_ 2561553175 Tire_Location 3192;
BA_ "SPN" SG_ 2561553175 Reference_Tire_Setting_Conmand 520334;
BA_ "SPN" SG_ 2566827543 ServiceBrakeAirPressureCircuit1 1087;
BA_ "SPN" SG_ 2566827543 ServiceBrakeAirPressureCircuit2 1088;
BA_ "SPN" SG_ 2566718743 EngineOilPressureLowLampData 5099;
BA_ "SPN" SG_ 2566718743 EngCoolantTempHighLampData 5100;
BA_ "SPN" SG_ 2566718743 EngineCoolantLevelLowLampData 5101;
BA_ "SPN" SG_ 2566718743 EngAIRFilterRestrictLampData 5103;
BA_ "SPN" SG_ 2566718743 BrakeAirPressureLowCircuit2 520338;
BA_ "SPN" SG_ 2566718743 BrakeAirPressureLowCircuit1 520337;
BA_ "SPN" SG_ 2566718743 LowFuelLevelLampData 520336;
BA_ "SPN" SG_ 2566718743 OBDMalfunctionIndicatorLampData 5096;
BA_ "SPN" SG_ 2566718743 EngineBrakeActiveLampData 5097;
BA_ "SPN" SG_ 2566847511 DistanceToempty2 520362;
BA_ "SPN" SG_ 2566847511 CargoAmbientTemperatureIC 169;
BA_ "SPN" SG_ 2566847511 DistanceToempty1 520339;
BA_ "SPN" SG_ 2566847511 FuelLevel 96;
BA_ "SPN" SG_ 2566843415 VehicleIdentificationNumber1 520340;
BA_ "GenSigSendType" SG_ 2566843415 VehicleIdentificationNumber1 4;
BA_ "GenSigSendType" SG_ 2566843415 VehicleIdentificationNumber3 4;
BA_ "SPN" SG_ 2566843415 DelimiterIC 520341;
BA_ "GenSigSendType" SG_ 2566843415 DelimiterIC 4;
BA_ "GenSigSendType" SG_ 2566843415 VehicleIdentificationNumber2 4;
BA_ "SPN" SG_ 2566904855 VehicleSpeedLimit 520342;
BA_ "GenSigSendType" SG_ 2566904855 VehicleSpeedLimit 3;
BA_ "SPN" SG_ 2566904855 EngineStartLimitStatus 520346;
BA_ "GenSigSendType" SG_ 2566904855 EngineStartLimitStatus 3;
BA_ "SPN" SG_ 2566904855 EngineTorqueLimitStatus 520345;
BA_ "GenSigSendType" SG_ 2566904855 EngineTorqueLimitStatus 3;
BA_ "SPN" SG_ 2566904855 VehicleSpeedLimitStatu 520344;
BA_ "GenSigSendType" SG_ 2566904855 VehicleSpeedLimitStatu 3;
BA_ "SPN" SG_ 2566904855 TorqueLimit 520343;
BA_ "GenSigSendType" SG_ 2566904855 TorqueLimit 3;
BA_ "SPN" SG_ 2566909975 IC_NM_DA 520347;
BA_ "SPN" SG_ 2566909975 IC_NM_Limphome 520350;
BA_ "SPN" SG_ 2566909975 IC_NM_Sleep_Ind 520351;
BA_ "SPN" SG_ 2566909975 IC_NM_Sleep_Ack 520352;
BA_ "SPN" SG_ 2566909975 IC_NM_Alive 520348;
BA_ "SPN" SG_ 2566909975 IC_NM_Ring 520349;
BA_ "SystemSignalLongSymbol" SG_ 2349541911 DriveractivationdemandforAdvance "DriveractivationdemandforAdvancedEmergencyBrakingSystem";
BA_ "SPN" SG_ 2566842094 Seconds 959;
BA_ "SPN" SG_ 2566842094 Hours 961;
BA_ "SPN" SG_ 2566842094 Month 962;
BA_ "SPN" SG_ 2566842094 Day 963;
BA_ "SPN" SG_ 2566842094 Year 964;
BA_ "SPN" SG_ 2566842094 LocalMinuteOffset 1601;
BA_ "SPN" SG_ 2566842094 LocalHourOffset 1602;
BA_ "SPN" SG_ 2566842094 Minutes 960;
BA_ "GenSigSendType" SG_ 2365526254 DriverCardNumber 4;
BA_ "GenSigSendType" SG_ 2365526254 DriverCardState 4;
VAL_ 2566869068 FMRadioChanel 255 "Invalid" ;
VAL_ 2566869068 USBConnectionStatus 3 "Reserved" 2 "error" 1 "connect" 0 "disconnect" ;
VAL_ 2566869068 BluetoothConnectionStatus 15 "Reserved" 14 "Reserved" 13 "Reserved" 12 "Reserved" 11 "Reserved" 10 "Reserved" 9 "Reserved" 8 "Reserved" 7 "Reserved" 6 "error" 5 "手机电量状态5" 4 "手机电量状态4" 3 "手机电量状态3" 2 "手机电量状态2" 1 "手机电量状态1" 0 "disconnect" ;
VAL_ 2566869068 FM_AM_MUSICStatus 3 "Reserved" 2 "music" 1 "AM" 0 "FM" ;
VAL_ 2566869068 PhoneStatus 3 "Reserved" 2 "error" 1 "on" 0 "off" ;
VAL_ 2566869068 VehicleDirectionStatus 3 "Reserved" 2 "error" 1 "on" 0 "off" ;
VAL_ 2566869068 AMRadioChanel 255 "Invalid" ;
VAL_ 2566869324 EHC5_St_FrameType 3 "End Frame" 2 "ConsecutiveFrame" 1 "The first Frame" 0 "Single" ;
VAL_ 2566869580 PhoneNumInternational1 15 "Invalid" ;
VAL_ 2566869580 PhoneNumInternational4 15 "Invalid" ;
VAL_ 2566869580 PhoneNum1 15 "Invalid" ;
VAL_ 2566869580 PhoneNum2 15 "Invalid" ;
VAL_ 2566869580 PhoneNum3 15 "Invalid" ;
VAL_ 2566869580 PhoneNum4 15 "Invalid" ;
VAL_ 2566869580 PhoneNum5 15 "Invalid" ;
VAL_ 2566869580 PhoneNum6 15 "Invalid" ;
VAL_ 2566869580 PhoneNumInternational2 15 "Invalid" ;
VAL_ 2566869580 PhoneNum7 15 "Invalid" ;
VAL_ 2566869580 PhoneNum8 15 "Invalid" ;
VAL_ 2566869580 PhoneNum9 15 "Invalid" ;
VAL_ 2566869580 PhoneNum10 15 "Invalid" ;
VAL_ 2566869580 PhoneNum11 15 "Invalid" ;
VAL_ 2566869580 PhoneNum12 15 "Invalid" ;
VAL_ 2566869580 PhoneNumInternational3 15 "Invalid" ;
VAL_ 2566869836 Volume_AddorSubtract 3 "invalid" 2 "风量-" 1 "风量+" 0 "undo" ;
VAL_ 2566869836 AUTO_switch 3 "invalid" 2 "error" 1 "enable" 0 "disable" ;
VAL_ 2566869836 OFF_switch 3 "invalid" 2 "error" 1 "enable" 0 "disable" ;
VAL_ 2566869836 Temp_AddorSubtract 3 "invalid" 2 "温度-" 1 "温度+" 0 "undo" ;
VAL_ 2566869836 Recurrent_Switch 3 "invalid" 2 "外循环" 1 "内循环" 0 "不按下" ;
VAL_ 2566869836 Acswitch 3 "invalid" 2 "error" 1 "enable" 0 "disable" ;
VAL_ 2566869836 MAX_Acswitch 3 "invalid" 2 "error" 1 "enable" 0 "disable" ;
VAL_ 2566869836 ModelSwitch 15 "invalid" 14 "error" 13 "Not available" 12 "Not available" 11 "Not available" 10 "Not available" 9 "Not available" 8 "Not available" 7 "Not available" 6 "最大除霜状态" 5 "除霜状态" 4 "模式吹脚除霜" 3 "模式吹脚" 2 "模式吹面吹脚" 1 "模式吹面" 0 "Not available" ;
VAL_ 2566842444 VehicleDirection 255 "NO GPS signal" 128 "northeast" 64 "north" 32 "northwest" 16 "west" 8 "southwest" 4 "south" 2 "southeast" 1 "east" ;
VAL_ 2566842444 NAV_DepartureWaring 3 "Reserved" 2 "error" 1 "yes" 0 "no" ;
VAL_ 2566842444 NAV_TurnWaring 7 "右后方" 6 "左后方" 5 "右前方" 4 "左前方" 3 "直行" 2 "右转" 1 "左转" 0 "掉头" ;
VAL_ 2566870092 TSR_Main_Switch 3 "Not set 未操作" 2 "Error" 1 "ON (TSR开启)" 0 "Off (TSR关闭)" ;
VAL_ 2566870092 LDW_Sensitivity 15 "Not set 未操作" 14 "Error" 3 "Level 3 (LDW等级，高)" 2 "Level 2" 1 "Level 1 (LDW等级，低)" 0 "Reserved" ;
VAL_ 2566870092 FCW_Main_Switch 3 "Not set 未操作" 2 "Error" 1 "ON (FCW开启)" 0 "Off (FCW关闭)" ;
VAL_ 2566870092 DDWS_SwitchOne 3 "Not set 未操作" 2 "Error" 1 "enable" 0 "disable" ;
VAL_ 2566870092 DDWS_SwitchTwo 3 "Not set 未操作" 2 "Error" 1 "enable" 0 "disable" ;
VAL_ 2566870092 FCW_Sensitivity 15 "Not set 未操作" 14 "Error" 3 "Level 3 (FCW等级，高)" 2 "Level 2" 1 "Level 1 (FCW等级，低)" 0 "Reserved" ;
VAL_ 2566870092 IHC_Main_Switch 3 "Not set 未操作" 2 "Error" 1 "ON (IHC开启)" 0 "Off (IHC关闭)" ;
VAL_ 2566910028 MP5_NM_DA 251 "TBOX" 76 "MP5" 52 "PEPS" 33 "BCM" 25 "EATC" 23 "ICM" ;
VAL_ 2566910028 MP5_NM_Limphome 1 "Ture" 0 "False" ;
VAL_ 2566910028 MP5_NM_Sleep_Ind 1 "Ture" 0 "False" ;
VAL_ 2566910028 MP5_NM_Sleep_Ack 1 "Ture" 0 "False" ;
VAL_ 2566910028 MP5_NM_Alive 1 "Ture" 0 "False" ;
VAL_ 2566910028 MP5_NM_Ring 1 "Ture" 0 "False" ;
VAL_ 2566877415 Eyes_closed_level1_alarm 1 "alarm" 0 "no alarm" ;
VAL_ 2566877415 Yawned 1 "yes" 0 "no" ;
VAL_ 2566877415 Distraction 1 "yes" 0 "no" ;
VAL_ 2566877415 CallPhone 1 "yes" 0 "no" ;
VAL_ 2566877415 SmokingWarning 3 "Reserved" 2 "Reserved" 1 "smoking" 0 "no smoking" ;
VAL_ 2566877415 WarningStatus 15 "Reserved" 14 "error" 13 "Occlusion waring(遮挡报警)" 12 "Reserved" 11 "Reserved" 10 "Reserved" 9 "Reserved" 8 "Reserved" 7 "Reserved" 6 "Reserved" 5 "Reserved" 4 "Reserved" 3 "3 level waring" 2 "2 level waring" 1 "1level waring" 0 "normal" ;
VAL_ 2566877415 WorkingState 15 "Reserved" 14 "error" 13 "Occlusion waring(遮挡报警)" 12 "Reserved" 11 "Reserved" 10 "Reserved" 9 "Reserved" 8 "Reserved" 7 "Reserved" 6 "Reserved" 5 "Reserved" 4 "Reserved" 3 "all  level waring active" 2 "2~3 level waring active" 1 "1 level waring active" 0 "all level waring  off" ;
VAL_ 2566877415 Eyes_closed_level2_alarm 1 "alarm" 0 "no alarm" ;
VAL_ 2566889497 ACReq 3 "Not available" 2 "error" 1 "valid" 0 "unvalid" ;
VAL_ 2566889497 Model_state 15 "Not available" 14 "error" 13 "Not available" 12 "Not available" 11 "Not available" 10 "Not available" 9 "Not available" 8 "Not available" 7 "Not available" 6 "最大除霜状态" 5 "除霜状态" 4 "模式吹脚除霜" 3 "模式吹脚" 2 "模式吹面吹脚" 1 "模式吹面" 0 "Not available" ;
VAL_ 2566889497 BlowerLvlStatus 15 "Not available" 14 "Not available" 13 "Not available" 12 "Not available" 11 "Not available" 10 "Not available" 9 "Not available" 8 "error" 7 "Level 7" 6 "Level 6" 5 "Level 5" 4 "Level 4" 3 "Level 3" 2 "Level 2" 1 "Level 1" 0 "level 0" ;
VAL_ 2566889497 MaxACReq 3 "Not available" 2 "error" 1 "valid" 0 "unvalid" ;
VAL_ 2566889497 CompressorOpeningStates 3 "Not available" 2 "error" 1 "open" 0 "close" ;
VAL_ 2566889497 DiagnosticEATC 15 "预留" 14 "预留" 13 "新风电机堵转" 12 "新风电机短路断路故障" 11 "温度电机堵转" 10 "温度电机短路断路" 9 "模式电机堵转" 8 "模式电机短路断路故障" 7 "鼓风机短路断路故障" 6 "吹脚传感器断路短路故障" 5 "吹面传感器断路短路故障" 4 "阳光传感器断路断路，" 3 "蒸发传感器断路短路故障" 2 "车外传感器断路短路(not support)" 1 "车内传感器断路短路" 0 "Not available" ;
VAL_ 2566889497 HeaterMirror_switch 3 "Not available" 2 "error" 1 "valid" 0 "unvalid" ;
VAL_ 2566889497 Recurrent_State 3 "Not available" 2 "error" 1 "内循环" 0 "外循环" ;
VAL_ 2566889497 AUTO_state 3 "Not available" 2 "error" 1 "open" 0 "close" ;
VAL_ 2566889497 OFF_state 3 "Not available" 2 "error" 1 "open" 0 "close" ;
VAL_ 2566841377 A_C_CompressorSwitch 3 "Not available" 2 "Error（故障状态）" 1 "A/C Compressor switch enable(high level)" 0 "A/C Compressor switch disable" ;
VAL_ 2566909977 EATC_NM_DA 251 "TBOX" 76 "MP5" 52 "PEPS" 33 "BCM" 25 "EATC" 23 "ICM" ;
VAL_ 2566909977 EATC_NM_Limphome 1 "Ture" 0 "False" ;
VAL_ 2566909977 EATC_NM_Sleep_Ind 1 "Ture" 0 "False" ;
VAL_ 2566909977 EATC_NM_Sleep_Ack 1 "Ture" 0 "False" ;
VAL_ 2566909977 EATC_NM_Alive 1 "Ture" 0 "False" ;
VAL_ 2566909977 EATC_NM_Ring 1 "Ture" 0 "False" ;
VAL_ 2566844672 Two_speed_axle_switch 3 "Not available" 2 "Error" 1 "High speed range" 0 "Low speed range" ;
VAL_ 2566844672 Parking_brake_switch 3 "Not available" 2 "Error" 1 "pressed" 0 "Not pressd" ;
VAL_ 2566844672 Cruise_Control_active 3 "Not available" 2 "Error" 1 "Cruise control switch on" 0 "Cruise control switch off" ;
VAL_ 2566844672 Cruise_Control_enable_switch 3 "Not available" 2 "Error" 1 "Cruise control abled" 0 "Cruise control disabled" ;
VAL_ 2566844672 Status_of_brake_switch 3 "Not available" 2 "Error" 1 "actuated" 0 "Not actuated" ;
VAL_ 2566844672 Status_of_clutch_switch 3 "Not available" 2 "Error" 1 "actuated" 0 "Not actuated" ;
VAL_ 2566844672 Cruise_Control_set_switch 3 "Not available" 2 "Error" 1 "actuated" 0 "Not actuated" ;
VAL_ 2566844672 Cruise_Control_coast_switch 3 "Not available" 2 "Error" 1 "actuated" 0 "Not actuated" ;
VAL_ 2566844672 Cruise_Control_resume_switch 3 "Not available" 2 "Error" 1 "actuated" 0 "Not actuated" ;
VAL_ 2566844672 Cruise_Control_accelerate_switch 3 "Not available" 2 "Error" 1 "actuated" 0 "Not actuated" ;
VAL_ 2566844672 Charge_Mode 15 "error" 14 "Mode 14" 13 "Mode 13" 12 "Mode 12" 11 "Mode 11" 10 "Mode 10" 9 "Mode 9" 8 "Mode 8" 7 "Mode 7" 6 "Mode 6" 5 "Mode 5" 4 "Mode 4" 3 "Mode 3" 2 "Mode 2" 1 "Mode 1" 0 "Mode 0" ;
VAL_ 2566844672 PTO_state 31 "Not available" 14 "Not defined" 13 "Preprogrammed set speed 4" 12 "Preprogrammed set speed 3" 11 "Preprogrammed set speed 2" 10 "Preprogrammed set speed 1" 9 "Not defined" 8 "Accelerate" 7 "Resume" 6 "Decelerate / Coast" 5 "set" 4 "Not defined" 3 "Standby / Neutral" 2 "Not defined" 1 "Hold" 0 "Off / Disabled" ;
VAL_ 2566844672 Cruise_Control_state 7 "Not available" 6 "Accelerator override" 5 "Set" 4 "Resume" 3 "Decelerate" 2 "Accelerate" 1 "Hold" 0 "Off / Disabled" ;
VAL_ 2566844672 IdleIncrementSwitch 3 "Not available" 2 "Error" 1 "ON" 0 "Off" ;
VAL_ 2566844672 IdleDecrementSwitch 3 "Not available" 2 "Error" 1 "ON" 0 "Off" ;
VAL_ 2566844672 EngineTestModeSwitch 3 "Not available" 2 "Error" 1 "ON" 0 "Off" ;
VAL_ 2566844672 Engine_shutdown_override_switch 3 "Not available" 2 "Error" 1 "ON" 0 "Off" ;
VAL_ 2364539648 AcceleratorPedal1LowIdleSwitch 3 "Not available" 2 "Error" 1 "Low idle switch signal active" 0 "Low idle switch signal not active" ;
VAL_ 2364539648 AcceleratorPedalKickdownSwitch 3 "Not available" 2 "Error" 1 "Kick-Down  active" 0 "Kick-Down not active" ;
VAL_ 2364539648 RoadSpeedLimitStatus 3 "Not available" 2 "Error" 1 "Not Active" 0 "Active" ;
VAL_ 2364539648 VehicleAccelRateLmtStatus 3 "Not available" 2 "Reserved" 1 "Limit  active" 0 "Limit not active" ;
VAL_ 2364539648 GearShiftIndication 3 "Not available" 2 "Error" 1 "Gear Shift Indication Telltale On" 0 "Gear Shift Indication Telltale Off" ;
VAL_ 2364539904 EngineTorqueMode 15 "Not available" 14 "VCU/PTO speed control / limit (not used)" 13 "VCU/PTO torque control / limit (not used)" 12 "Torque limitation because of fuel limitation" 11 "Not Used (Remote Acceleration)" 10 "Engine retarder control" 9 "High speed governor" 8 "Torque limiting" 7 "ABS control" 6 "Transmission control" 5 "ASR control" 4 "Road speed governor" 3 "PTO governor" 2 "Cruise control" 1 "Accelerator pedal/operator selection" 0 "Low idle  (default  mode)" ;
VAL_ 2364539904 ActualEnginePercentTorque_Fracti 15 "not avallable" 14 "not avallable" 13 "not avallable" 12 "not avallable" 11 "not avallable" 10 "not avallable" 9 "not avallable" 8 "not avallable" 7 "+0.875%" 1 "+0.125%" 0 "+0.000%" ;
VAL_ 2364539904 SourceAddofCtrlDeviceforEngCtrl 5 "VM controls the engine torque" 4 "Gear Box controls the engine torque" 3 "PTO controls the engine torque" 2 "Retarder controls the engine torque" 1 "ABS/ASR controls the engine torque" 0 "no external intervention, EDC controls the engine torque" ;
VAL_ 2364539904 EngineStarterMode 15 "Not available (no ECM request to stop cranking)" 14 "Error (ECM request to stop cranking)" 12 "Started inhibited – reason unknown" 7 "Starter inhibited due to Immobilizer (not used)" 6 "Starter inhibited due to driveline engaged (not used)" 5 "Starter inhibited due to engine not ready for start" 4 "Starter inhibited due to engine already running" 3 "Starter finished" 2 "Starter active, gear engaged (not used)" 1 "Starter active, gear not engaged (not used)" 0 "Start not requested" ;
VAL_ 2566844928 InstantaneousFuelEconomy 65024 "Vehicle speed error:" 64256 "Division by zero error" ;
VAL_ 2565865487 RetarderTorqueMode 15 "Not available" 14 "VCM negative torque demand" 13 "not defined" 12 "not defined" 11 "not defined" 10 "Retarder control" 9 "high speed governor" 8 "Torque limiter" 7 "ABS control" 6 "Transmission control" 5 "ASR control" 4 "Road Speed limiter" 3 "Power Take Off governor" 2 "Cruise Control" 1 "Operator seletion" 0 "No request" ;
VAL_ 2565865487 EngineCoolantLoadIncrease 3 "Not available" 2 "Error" 1 "coolant load increase" 0 "No coolant load increase" ;
VAL_ 2565865487 RetarderRequestingBrakeLight 3 "Not available" 2 "Reserved" 1 "Retarder is requesting that the brake lights are illuminated" 0 "Retarder is not requesting that the brake lights are illuminated" ;
VAL_ 2565865487 RetarderEnableBrakeAssistSwitch 3 "Not available" 2 "Error" 1 "Retarder-brake assist enabled" 0 "Retarder-brake assist disabled" ;
VAL_ 2565865487 RetarderEnableShiftAssistSwitch 3 "Not available" 2 "Error" 1 "Retarder-shift assist enabled" 0 "Retarder-shift assist disabled" ;
VAL_ 2566804992 SCRSpecMsgAdBlueUreaWarnLvlChain 7 "Not available" 4 "Fill up Adblue" 1 "AdBlue level Low" 0 "NO waring message" ;
VAL_ 2566804992 SCRSpecificMessagesAdBlueQuality 7 "Not available" 1 "incorrect AdBule" 0 "no waring message" ;
VAL_ 2566841344 IdleShutdownHasShutdownEngine 3 "not available" 2 "error" 1 "Yes" 0 "No" ;
VAL_ 2566841344 IdleShutdownTimerFunction 3 "Not available" 2 "Error" 1 "Enabled in calibration" 0 "Disabled in calibration" ;
VAL_ 2566841344 A_CHighPressureFanSwitch 3 "Not available" 2 "Error" 1 "Pressure high, fan may be engaged" 0 "Pressure normal" ;
VAL_ 2566841344 RefrigerantLowPressureSwitch 3 "Not available" 2 "Error" 1 "Pressure high, fan may be engaged" 0 "Pressure normal" ;
VAL_ 2566841344 EngIdleShutdownDriverAlertMode 3 "Not available" 2 "Error" 1 "Active" 0 "Inactive" ;
VAL_ 2566841344 RefrigerantHighPressureSwitch 3 "Not available" 2 "Error" 1 "Pressure high, fan may be engaged" 0 "Pressure normal" ;
VAL_ 2566841344 WaitToStartLamp 3 "Not available" 2 "Error" 1 "On" 0 "Off" ;
VAL_ 2566841344 EngProtectSystemHasShutdownEng 3 "Not available" 2 "Error" 1 "Yes" 0 "No" ;
VAL_ 2566841344 EngProtectSystemApproachShutdown 3 "Not available" 2 "Error" 1 "Approaching" 0 "Not approaching" ;
VAL_ 2566841344 EngProtectionSystemTimerOverride 3 "Not available" 2 "Error" 1 "Active" 0 "Inactive" ;
VAL_ 2566841344 EngineProtectionSystemTimerState 3 "Not available" 2 "Error" 1 "Active" 0 "Inactive" ;
VAL_ 2566841344 IdleShutdownTimerOverride 3 "Not available" 2 "Error" 1 "Active" 0 "Inactive" ;
VAL_ 2566841344 EngProtectionSystemConfig 3 "Not available" 2 "Error" 1 "Enabled in calibration" 0 "Disabled in calibration" ;
VAL_ 2566841344 EngineAlarmAcknowledge 3 "Not available" 2 "Error" 1 "Active" 0 "Inactive" ;
VAL_ 2566841344 EngineAlarmOutputCommandStatus 3 "Not available" 2 "Error" 1 "Active" 0 "Inactive" ;
VAL_ 2566841344 EngineAirShutoffCommandStatus 3 "Not available" 2 "reserved" 1 "enabled" 0 "Disabled" ;
VAL_ 2566841344 EngineOverspeedTest 3 "Not available" 2 "Error" 1 "Active" 0 "Inactive" ;
VAL_ 2566841344 EngineAirShutoffStatus 3 "Not available" 2 "Error" 1 "Air flow restricted" 0 "Air flow allowed to engine" ;
VAL_ 2566841344 IdleShutdownTimerState 3 "Not available" 2 "Error" 1 "Active" 0 "Inactive" ;
VAL_ 2566848256 WaterInFuelIndicator 3 "Not available" 2 "Not available" 1 "water presents in the fuel" 0 "No water presents in the fuel" ;
VAL_ 2566848256 SCRSpecificMessagesTampering 7 "Not available" 6 "Reserved" 5 "Reserved" 4 "Reserved" 3 "Reserved" 2 "Reserved" 1 "Critical Emissions Failure" 0 "No warning message" ;
VAL_ 2566848256 ClutchProtectionWarning 3 "error" 2 "Blinking clutch warning lamp" 1 "Continuous clutch warning lamp" 0 "No warning message" ;
VAL_ 2566848256 ClutchProtectionBuzzer 3 "error" 2 "Blinking Buzzer" 1 "Continuous Buzzer" 0 "No Buzzer" ;
VAL_ 2566848256 EngFuelFiltRestricLampCommand 3 "NA" 2 "NA" 1 "Lamp On" 0 "Lamp Off" ;
VAL_ 2566848256 OilChangeWarningIndicator 3 "Error State (Blink @ 2Hz)" 2 "Lamp On (Blinking @ 1 Hz) (high priority)" 1 "Lamp On (Continuous)" 0 "Lamp Off" ;
VAL_ 2566848256 LowOilIndicatorStatus 4 "Overfill warning" 3 "Not defined" 2 "Low oil warning" 1 "Critical Low Oil level" 0 "Oil Level OK" ;
VAL_ 2566848256 OLSTextMessageWarning 3 "Not available" 2 "error" 1 "Text Warning Enabled" 0 "Text Warning Disabled" ;
VAL_ 2566848256 SCRSpecificMessagesAdblue 7 "Not available" 6 "Reserved" 5 "Reserved" 4 "Reserved" 3 "Reserved" 2 "Reserved" 1 "AdBlue Dosing Malfunction" 0 "No warning message" ;
VAL_ 2566754816 EngineOperatingState 15 "not available" 7 "Post-Run" 6 "Engine Stopping" 5 "Cool-down" 4 "Running" 3 "Warm-Up" 2 "Starting" 1 "Pre-Start" 0 "Engine Stopped" ;
VAL_ 2566843648 ASLD_State 7 "Not available" 6 "reserved" 5 "reserved" 4 "Exceeding limit" 3 "Accelerator override" 2 "Active" 1 "Standby" 0 "off/Disable" ;
VAL_ 2566852608 EMS_ReleaseSig_PEPS 7 "Alogrithm Fail" 6 "Alogrithm Pass" 5 "Sendseed" 4 "cancel start success" 3 "cancel start fail" 2 "start success" 1 "start faile" 0 "Reserved" ;
VAL_ 2566852608 EMS_ReleaseSig_IMMO 3 "Reserved" 2 "invalid" 1 "passed" 0 "failed" ;
VAL_ 2566749184 Diesel_Particulate_Filter_Status 7 "not available" 6 "Regeneration  condition not met" 5 "Regeneration  in progress" 4 "deactive inhibition when possible" 3 "Regeneration  needed-highest level" 2 "Regeneration  needed-moderate level" 1 "Regeneration  needed-lowest level" 0 "Regeneration not needed" ;
VAL_ 2566749184 ECM_ExhaustOverheatStatus 3 "NA" 2 "NA" 1 "Exhaust OverHeat Protection active" 0 "Exhaust OverHeat Protection inactive" ;
VAL_ 2566749184 ECM_DPF_ActRegInhSw 3 "not available" 2 "reserved" 1 "inhibited 2" 0 "not inhibited 2" ;
VAL_ 2566749184 ECM_DPF_ActRegInhsysflt 3 "not available" 2 "reserved" 1 "inhibited" 0 "not inhibited" ;
VAL_ 2566749184 ECM_ExstSysHTemLampComm 3 "not available" 2 "reserved" 1 "high Exhaust System Temperature" 0 "Low Exhaust System Temperature" ;
VAL_ 2566849024 ECM_SootLoad 15 "Error" 14 "Error" 13 "Error" 12 "Error" 11 "Error" 10 "all bars blinking" 9 "First 9 bar are filled and blinks" 8 "8th bar filled" 7 "7th bar filled" 6 "6th bar filled" 5 "5th bar filled" 4 "4th bar filled" 3 "3rd bar filled" 2 "2nd bar filled" 1 "1st bar filled" 0 "No bar filled" ;
VAL_ 2566849024 ECM_ManualRegenStatus 3 "not Available" 2 "error" 1 "Regen in Progress" 0 "Regen not in Progress" ;
VAL_ 2565865739 ATCEngineControlActive 3 "Not available" 2 "Reserved" 1 "ATC engine control active" 0 "ATC engine control passive" ;
VAL_ 2565865739 ABSoff_roadswitch 3 "The ECU has no input for a ABS 0ff-road switch" 2 "Not Supported" 1 "ABS off-road switch active" 0 "ABS off-road switch passive" ;
VAL_ 2565865739 ATCoff_roadswitch 3 "Not available" 2 "Error" 1 "ATC off-road switch active" 0 "ATC off-road switch passive" ;
VAL_ 2565865739 ATCBrakeControlActive 3 "Not available" 2 "Reserved" 1 "ATC brake control  active" 0 "ATC brake control passive" ;
VAL_ 2565865739 ASRHillHolderSwitch 3 "Not available" 2 "Error" 1 "ATC off-road switch active" 0 "ATC off-road switch passive" ;
VAL_ 2565865739 TractionControlOverrideSwitch 3 "Not available or not installed" 2 "Error" 1 "On" 0 "Off" ;
VAL_ 2565865739 AcceleratorInterlockSwitch 3 "Not available" 2 "Error" 1 "On" 0 "Off" ;
VAL_ 2565865739 EngineDerateSwitch 3 "Not available" 2 "Error" 1 "On" 0 "Off" ;
VAL_ 2565865739 EngineAuxiliaryShutdownSwitch 3 "Not available" 2 "Error" 1 "On" 0 "Off" ;
VAL_ 2565865739 RemoteAcceleratorEnableSwitch 3 "Not available" 2 "Error" 1 "On" 0 "Off" ;
VAL_ 2565865739 ABSActive 3 "Not available" 2 "Reserved" 1 "ABS active" 0 "ABS passive but installed" ;
VAL_ 2565865739 ABSfullyOperational 3 "Not available" 2 "Reserved" 1 "Fully Operational" 0 "Not Fully Operational" ;
VAL_ 2565865739 EBSRedWarningSignal 3 "Take no action" 2 "Reserved" 1 "On" 0 "Off" ;
VAL_ 2565865739 ABS_EBSamberWarningState 3 "Not available" 2 "Reserved" 1 "on" 0 "off" ;
VAL_ 2565865739 ATCLampState 3 "Not available" 2 "Reserved" 1 "on" 0 "off" ;
VAL_ 2565865739 EBSBrakeSwitch 3 "Not available" 2 "Error" 1 "Brake pedal is being pressed" 0 "Brake pedal is not being pressed" ;
VAL_ 2566834699 ProtectLampStateABS 3 "Not available" 2 "Not available" 1 "on" 0 "off" ;
VAL_ 2566834699 AmberWarningLampStatusABS 3 "Not available" 2 "Not available" 1 "on" 0 "off" ;
VAL_ 2566834699 FMIABS 31 "Condition Exists" 21 "Data Drifted Low" 20 "Data Drifted High" 19 "Received Network Data In Error" 18 "Data Valid But Below Normal Operating Range - Moderately Severe Level" 17 "Data Valid But Below Normal Operating Range - Least Severe Level" 16 "Data Valid But Above Normal Operating Range - Moderately Severe Level" 15 "Data Valid But Above Normal Operating Range - Least Severe Level" 14 "Special Instructions" 13 "Out Of Calibration" 12 "Bad Intelligent Device Or Component" 11 "Root Cause Not Known" 10 "Abnormal Rate Of Change" 9 "Abnormal Update Rate" 8 "Abnormal Frequency Or Pulse Width Or Period" 7 "Mechanical System Not Responding Or Out Of Adjustment" 6 "Current Above Normal Or Grounded Circuit" 5 "Current Below Normal Or Open Circuit" 4 "Voltage Below Normal, Or Shorted To Low Source" 3 "Voltage Above Normal, Or Shorted To High Source" 2 "Data Erratic, Intermittent Or Incorrect" 1 "Data Valid But Below Normal Operational Range - Most Severe Level" 0 "Data Valid But Above Normal Operational Range - Most Severe Level" ;
VAL_ 2566834699 RedStopLampZStatusABS 3 "Not available" 2 "Not available" 1 "on" 0 "off" ;
VAL_ 2566834699 OccurrenceCountABS 127 "Not available" ;
VAL_ 2566834699 MalfunctionIndicatorLampStatusAB 3 "Not available" 2 "Not available" 1 "on" 0 "off" ;
VAL_ 2633935883 BraLinRemainFrAxleLWheel 255 "Invalid" ;
VAL_ 2633935883 BraLinRemainRearAx1LWheel 255 "Invalid" ;
VAL_ 2633935883 BraLinRemainRearAx1RWheel 255 "Invalid" ;
VAL_ 2633935883 BraLinRemainRearAx2LWheel 255 "Invalid" ;
VAL_ 2633935883 BraLinRemainRearAx2RWheel 255 "Invalid" ;
VAL_ 2633935883 BraLinRemainRearAx3LWheel 255 "Invalid" ;
VAL_ 2633935883 BraLinRemainRearAx3RWheel 255 "Invalid" ;
VAL_ 2633935883 BraLinRemainFrAxRWheel 255 "Invalid" ;
VAL_ 2566767627 BrakeTemperatureWarn 3 "not available" 2 "Reserved" 1 "Active" 0 "Not Active" ;
VAL_ 2566767627 XBRSystemState 3 "not available" 2 "No external brake demand will be accepted (e.g. because of fault in brake system)" 1 "Only external brake demand of highest XBR Priority (00) will be accepted  (e.g. because the temperature limit of the brake system is exceeded)" 0 "Any external brake demand will be accepted (brake system fully operational)" ;
VAL_ 2566767627 XBRActiveControlMode 15 "Not available" 14 "Reserved for SAE assignment" 13 "Reserved for SAE assignment" 12 "Reserved for SAE assignment" 11 "Reserved for SAE assignment" 10 "Reserved for SAE assignment" 9 "Reserved for SAE assignment" 8 "Reserved for SAE assignment" 7 "Reserved for SAE assignment" 6 "Reserved for SAE assignment" 5 "Reserved for SAE assignment" 4 "Reserved for SAE assignment" 3 "Maximum mode of XBR acceleration control being executed" 2 "Addition mode of XBR acceleration control being executed" 1 "Driver's brake demand being executed, no external brake demand" 0 "No brake demand being executed (default mode)" ;
VAL_ 2566767627 Haltbrakemode 7 "Not available" 6 "Halt brake not functional" 5 "Not defined" 4 "Not defined" 3 "Not defined" 2 "Active, but not functioning properly.  (This mode may be used to warn the driver)" 1 "Active" 0 "Inactive" ;
VAL_ 2566767627 Hillholdermode 7 "Not available" 6 "Hill holder not functional" 5 "Reserved" 4 "Reserved" 3 "Reserved" 2 "Active, but will change to inactive in a short time.  (This mode may be used to warn the driver)" 1 "Active" 0 "Inactive" ;
VAL_ 2566767627 FoundationBrakeUse 3 "Not available" 2 "Reserved" 1 "Foundation brakes in use" 0 "Foundation brakes not in use" ;
VAL_ 2566803211 VDCLampState 3 "Don't care/Take no action" 2 "Reserved" 1 "On" 0 "Off" ;
VAL_ 2566803211 ROPBrakeCrlactive 3 "Don't care/Take no action" 2 "Reserved" 1 "ROP brake control active" 0 "ROP brake control passive but installed" ;
VAL_ 2566803211 YCEngineCrlactive 3 "Don't care/Take no action" 2 "Reserved" 1 "YC engine control active" 0 "YC engine control passive but installed" ;
VAL_ 2566803211 YCBrakeCrlactive 3 "Don't care/Take no action" 2 "Reserved" 1 "YC brake control active" 0 "YC brake control passive but installed" ;
VAL_ 2566803211 VDCFullyOperational 3 "Don't care/Take no action" 2 "Reserved" 1 "Fully operational" 0 "Not fully operational" ;
VAL_ 2566803211 VDCbrakelightrequest 3 "Don't care/Take no action" 2 "Reserved" 1 "Turn brake light on" 0 "Turn brake light not on" ;
VAL_ 2566803211 ROPEngineCrlactive 3 "Don't care/Take no action" 2 "Reserved" 1 "ROP engine control active" 0 "ROP engine control passive but installed" ;
VAL_ 2566838539 Auxiliary08 3 "Not available" 2 "Error" 1 "Activate door brake" 0 "Release door brake" ;
VAL_ 2566838539 Auxiliary07 3 "Not available" 2 "Error" 1 "Supply pressure sufficient" 0 "Supply pressure insufficient" ;
VAL_ 2566838539 Auxiliary03 3 "Not available" 2 "Error" 1 "Halt brake mode active" 0 "Halt brake mode inactive" ;
VAL_ 2566838539 Auxiliary06 3 "Not available" 2 "Error" 1 "Differential lock engaged" 0 "Differential lock disengaged" ;
VAL_ 2566838539 Auxiliary05 3 "Not available" 2 "Error" 1 "Parking brake set" 0 "Parking brake not set" ;
VAL_ 2566838539 Auxiliary09 3 "Not available" 2 "Error" 1 "Retarder integration enabled" 0 "Retarder integration disabled" ;
VAL_ 2566838539 Auxiliary02 3 "Not available" 2 "Error" 1 "Requested brake light on" 0 "Requested brake light off" ;
VAL_ 2566838539 Auxiliary01 3 "Not available" 2 "Error" 1 "Brake assist on" 0 "Brake assist off" ;
VAL_ 2566838551 CabinTiltSwitch 3 "Not available" 2 "error" 1 "Cabin  Tilt" 0 "Cabin Not Tilt" ;
VAL_ 2566838551 RetarderLeverPosition 3 "Not available" 2 "error" 1 "Engine Brake/Intarder Lever position on" 0 "Engine Brake/Intarder Lever position off" ;
VAL_ 2566838551 AverageSpeedA 65535 "Not Available/Take No Action" 65279 "Error" ;
VAL_ 2566838551 TrailerBrakestatus 3 "Not available" 2 "error" 1 "Trailer Brake active" 0 "Trailer brake inactive" ;
VAL_ 2566838551 AverageSpeedB 65535 "Not Available/Take No Action" 65279 "Error" ;
VAL_ 2566838551 OilChangedStatus 3 "Not available" 2 "error" 1 "Oil Changed" 0 "Oil Not Changed" ;
VAL_ 2566838551 Gearboxneutralposition 3 "Not available" 2 "error" 1 "Secured neutral position" 0 "Not in secured neutral position" ;
VAL_ 2566848791 AlternatorChargingIndicatorLamp 3 "NotAvailable" 2 "error" 1 "Lamp activated(On)" 0 "Lamp deactivated(Off)" ;
VAL_ 2566848791 MainStatus 3 "NotAvailable" 2 "主题3" 1 "主题2" 0 "主题1" ;
VAL_ 2566848791 CurrentRunningComputer 3 "NotAvailable" 2 "NOT Available" 1 "行车电脑B" 0 "行车电脑A" ;
VAL_ 2566848791 AverageFuelEconomyB 65535 "Not Available/Take No Action" 65279 "Error" ;
VAL_ 2566848791 SeatBeltIndicatorLamp 3 "NotAvailable" 2 "error" 1 "Lamp activated(On)" 0 "Lamp deactivated(Off)" ;
VAL_ 2566848791 GearHighLowStateTelltale 3 "NotAvailable" 2 "error" 1 "高档" 0 "低档" ;
VAL_ 2566848791 PTOIndicatorLamp 3 "NotAvailable" 2 "error" 1 "Lamp activated(On)" 0 "Lamp deactivated(Off)" ;
VAL_ 2566848791 TrailerABSIndicatorLamp 3 "NotAvailable" 2 "error" 1 "Lamp activated(On)" 0 "Lamp deactivated(Off)" ;
VAL_ 2566805015 RemainingOilAuxiliaryTank 255 "Not Available/Take No Action" 254 "Error" ;
VAL_ 2566805015 UseOilBox 3 "Reserved" 2 "Reserved" 1 "AuxiliaryTank（副油箱）" 0 "MainTank（主油箱）" ;
VAL_ 2566805015 RemainingOilMainTank 255 "Not Available/Take No Action" 254 "Error" ;
VAL_ 2566849047 TSR_Main_SwitchIC 3 "Not set 未操作" 2 "Error" 1 "ON (TSR开启)" 0 "Off (TSR关闭)" ;
VAL_ 2566849047 NV_IntelligentSwitchC 3 "Not set 未操作" 2 "Error" 1 "ON (NV开启)" 0 "Off (NV关闭)" ;
VAL_ 2566849047 LDW_SensitivityIC 15 "Not set 未操作" 14 "Error（故障状态）" 3 "Level 3 (LDW等级，高)" 2 "Level 2" 1 "Level 1 (LDW等级，低)" 0 "Reserved" ;
VAL_ 2566849047 FCW_Main_SwitchIC 3 "Not set 未操作" 2 "Error" 1 "ON (FCW开启)" 0 "Off (FCW关闭)" ;
VAL_ 2566849047 DDWS_SwitchIC 3 "Not set 未操作" 2 "Error" 1 "enable" 0 "disable" ;
VAL_ 2566849047 OK_Switch 3 "Not set 未操作" 2 "Error" 1 "enable" 0 "disable" ;
VAL_ 2566849047 DDWS_SwitchICtwo 3 "Not set 未操作" 2 "error" 1 "enable" 0 "disable" ;
VAL_ 2566849047 FCW_SensitivityIC 15 "Not set 未操作" 14 "Error（故障状态）" 3 "Level 3 (FCW等级，高)" 2 "Level 2" 1 "Level 1 (FCW等级，低)" 0 "Reserved" ;
VAL_ 2566849047 IHC_Main_SwitchIC 3 "Not set 未操作" 2 "Error" 1 "ON (IHC开启)" 0 "Off (IHC关闭)" ;
VAL_ 2566844951 AverageFuelEconomyA 65535 "Not Available/Take No Action" 65279 "Error" ;
VAL_ 2561553175 Reference_Tire_Setting_Conmand 255 "Reserved" 254 "Reserved" 253 "Reserved" 252 "Reserved" 251 "Reserved" 250 "Reserved" 249 "Reserved" 248 "Reserved" 247 "Reserved" 246 "Reserved" 245 "Reserved" 244 "Reserved" 243 "Reserved" 242 "Reserved" 241 "Reserved" 240 "Reserved" 239 "Reserved" 238 "Reserved" 237 "Reserved" 236 "Reserved" 235 "Reserved" 234 "Reserved" 233 "Reserved" 232 "Reserved" 231 "Reserved" 230 "Reserved" 229 "Reserved" 228 "Reserved" 227 "Reserved" 226 "Reserved" 225 "Reserved" 224 "Reserved" 223 "Reserved" 222 "Reserved" 221 "Reserved" 220 "Reserved" 219 "Reserved" 218 "Reserved" 217 "Reserved" 216 "Reserved" 215 "Reserved" 214 "Reserved" 213 "Reserved" 212 "Reserved" 211 "Reserved" 210 "Reserved" 209 "Reserved" 208 "Reserved" 207 "Reserved" 206 "Reserved" 205 "Reserved" 204 "Reserved" 203 "Reserved" 202 "Reserved" 201 "Reserved" 200 "Reserved" 199 "Reserved" 198 "Reserved" 197 "Reserved" 196 "Reserved" 195 "Reserved" 194 "Reserved" 193 "Reserved" 192 "Reserved" 191 "Reserved" 190 "Reserved" 189 "Reserved" 188 "Reserved" 187 "Reserved" 186 "Reserved" 185 "Reserved" 184 "Reserved" 183 "Reserved" 182 "Reserved" 181 "Reserved" 180 "Reserved" 179 "Reserved" 178 "Reserved" 177 "Reserved" 176 "Reserved" 175 "Reserved" 174 "Reserved" 173 "Reserved" 172 "Reserved" 171 "Reserved" 170 "Reserved" 169 "Reserved" 168 "Reserved" 167 "Reserved" 166 "Reserved" 165 "Reserved" 164 "Reserved" 163 "Reserved" 162 "Reserved" 161 "Reserved" 160 "Reserved" 159 "Reserved" 158 "Reserved" 157 "Reserved" 156 "Reserved" 155 "Reserved" 154 "Reserved" 153 "Reserved" 152 "Reserved" 151 "Reserved" 150 "Reserved" 149 "Reserved" 148 "Reserved" 147 "Reserved" 146 "Reserved" 145 "Reserved" 144 "Reserved" 143 "Reserved" 142 "Reserved" 141 "Reserved" 140 "Reserved" 139 "Reserved" 138 "Reserved" 137 "Reserved" 136 "Reserved" 135 "Reserved" 134 "Reserved" 133 "Reserved" 132 "Reserved" 131 "Reserved" 130 "Reserved" 129 "Reserved" 128 "Reserved" 127 "Reserved" 126 "Reserved" 125 "Reserved" 124 "Reserved" 123 "Reserved" 122 "Reserved" 121 "Reserved" 120 "Reserved" 119 "Reserved" 118 "Reserved" 117 "Reserved" 116 "Reserved" 115 "Reserved" 114 "Reserved" 113 "Reserved" 112 "Reserved" 111 "Reserved" 110 "Reserved" 109 "Reserved" 108 "Reserved" 107 "Reserved" 106 "Reserved" 105 "Reserved" 104 "Reserved" 103 "Reserved" 102 "Reserved" 101 "Reserved" 100 "Reserved" 99 "Reserved" 98 "Reserved" 97 "Reserved" 96 "Reserved" 95 "Reserved" 94 "Reserved" 93 "Reserved" 92 "Reserved" 91 "Reserved" 90 "Reserved" 89 "Reserved" 88 "Reserved" 87 "Reserved" 86 "Reserved" 85 "Reserved" 84 "Reserved" 83 "Reserved" 82 "Reserved" 81 "Reserved" 80 "Reserved" 79 "Reserved" 78 "Reserved" 77 "Reserved" 76 "Reserved" 75 "Reserved" 74 "Reserved" 73 "Reserved" 72 "Reserved" 71 "Reserved" 70 "Reserved" 69 "Reserved" 68 "Reserved" 67 "Reserved" 66 "Reserved" 65 "Reserved" 64 "Reserved" 63 "Reserved" 62 "Reserved" 61 "Reserved" 60 "Reserved" 59 "Reserved" 58 "Reserved" 57 "Reserved" 56 "Reserved" 55 "Reserved" 54 "Reserved" 53 "Reserved" 52 "Reserved" 51 "Reserved" 50 "Reserved" 49 "Reserved" 48 "Reserved" 47 "Reserved" 46 "Reserved" 45 "Reserved" 44 "Reserved" 43 "Reserved" 42 "Reserved" 41 "Reserved" 40 "Reserved" 39 "Reserved" 38 "Reserved" 37 "Reserved" 36 "Reserved" 35 "Reserved" 34 "Reserved" 33 "Reserved" 32 "Reserved" 31 "Reserved" 30 "Reserved" 29 "Reserved" 28 "Reserved" 27 "Reserved" 26 "Reserved" 25 "Reserved" 24 "Reserved" 23 "Reserved" 22 "Reserved" 21 "Reserved" 20 "Reserved" 19 "Reserved" 18 "Reserved" 17 "Reserved" 16 "Reserved" 15 "Reserved" 14 "Reserved" 13 "Reserved" 12 "Reserved" 11 "Reserved" 10 "Reserved" 9 "Reserved" 8 "Reserved" 7 "Reserved" 6 "Exit ID Learn Mode" 5 "Enter ID Learn Mode" 4 "Reserved" 3 "Reserved" 2 "Reserved" 1 "Reserved" 0 "Reserved" ;
VAL_ 2566827543 ServiceBrakeAirPressureCircuit1 255 "Not Available/Take No Action" 254 "Error" ;
VAL_ 2566827543 ServiceBrakeAirPressureCircuit2 255 "Not Available/Take No Action" 254 "Error" ;
VAL_ 2566718743 EngineOilPressureLowLampData 3 "Reserved" 2 "error" 1 "Lamp deactivated(On)" 0 "Lamp deactivated(Off)" ;
VAL_ 2566718743 EngCoolantTempHighLampData 3 "Reserved" 2 "error" 1 "Lamp deactivated(On)" 0 "Lamp deactivated(Off)" ;
VAL_ 2566718743 EngineCoolantLevelLowLampData 3 "Reserved" 2 "error" 1 "Lamp deactivated(On)" 0 "Lamp deactivated(Off)" ;
VAL_ 2566718743 EngAIRFilterRestrictLampData 3 "Reserved" 2 "error" 1 "Lamp deactivated(On)" 0 "Lamp deactivated(Off)" ;
VAL_ 2566718743 BrakeAirPressureLowCircuit2 3 "Reserved" 2 "error" 1 "Lamp deactivated(On)" 0 "Lamp deactivated(Off)" ;
VAL_ 2566718743 BrakeAirPressureLowCircuit1 3 "Reserved" 2 "error" 1 "Lamp deactivated(On)" 0 "Lamp deactivated(Off)" ;
VAL_ 2566718743 LowFuelLevelLampData 3 "Reserved" 2 "error" 1 "Lamp deactivated(On)" 0 "Lamp deactivated(Off)" ;
VAL_ 2566718743 OBDMalfunctionIndicatorLampData 3 "Reserved" 2 "error" 1 "Lamp deactivated(On)" 0 "Lamp deactivated(Off)" ;
VAL_ 2566718743 EngineBrakeActiveLampData 3 "Reserved" 2 "error" 1 "Lamp deactivated(On)" 0 "Lamp deactivated(Off)" ;
VAL_ 2566847511 DistanceToempty2 65535 "Not Available/Take No Action" 65279 "Error" ;
VAL_ 2566847511 CargoAmbientTemperatureIC 0 "发动机要求第一帧报文为FEFF(INTERL格式)" ;
VAL_ 2566847511 DistanceToempty1 65535 "Not Available/Take No Action" 65279 "Error" ;
VAL_ 2566847511 FuelLevel 255 "Not Available/Take No Action" 254 "Error indicator" ;
VAL_ 2566904855 EngineStartLimitStatus 3 "Not Available" 2 "error" 1 "Engine Start Limit activate" 0 "Engine Start Limit Deactivate" ;
VAL_ 2566904855 EngineTorqueLimitStatus 3 "Not Available" 2 "error" 1 "Engine Torque Limit activate" 0 "Engine Torque Limit Deactivate" ;
VAL_ 2566904855 VehicleSpeedLimitStatu 3 "Not Available" 2 "error" 1 "Vehicle Speed Limit activate" 0 "Vehicle Speed Limit Deactivate" ;
VAL_ 2566909975 IC_NM_DA 251 "TBOX" 76 "MP5" 52 "PEPS" 33 "BCM" 25 "EATC" 23 "ICM" ;
VAL_ 2566909975 IC_NM_Limphome 1 "Ture" 0 "False" ;
VAL_ 2566909975 IC_NM_Sleep_Ind 1 "Ture" 0 "False" ;
VAL_ 2566909975 IC_NM_Sleep_Ack 1 "Ture" 0 "False" ;
VAL_ 2566909975 IC_NM_Alive 1 "Ture" 0 "False" ;
VAL_ 2566909975 IC_NM_Ring 1 "Ture" 0 "False" ;
VAL_ 2349541911 DriveractivationdemandforAdvance 3 "reserved" 2 "error" 1 "the driver wants the Advanced Emergency Braking      System to warn or intervene if necessary (no deactivation    of system)" 0 "the driver does not want the Advanced Emergency Braking System to warn or intervene at any time (deactivation of system)" ;
VAL_ 2365526254 DriverCardState 3 "Reserved" 2 "Reserved" 1 "have  Card" 0 "Not Card" ;
